VERSION ""

NS_ :

BS_:

BU_: TBOX IPK PEPS BCM EPS ABS AVAS ACU GW VCU PTC ACCM MMI Vector_XXX BMSH IPU OBC BMS
VAL_TABLE_ ACCM_ERROR 1 "Error" 0 "normal" ;
VAL_TABLE_ ACCM_CompressorPower 255 "低压高压都有,但是压缩机不工作" 254 "只有低压没有高压,压缩机不工作" ;
VAL_TABLE_ AVAS_AVASDisabledSts 1 "Disable" 0 "Enable" ;
VAL_TABLE_ VCU_ModeGearDisplaySts_BCM 4 "D" 3 "P" 2 "R" 1 "reserved" 0 "Display" ;
VAL_TABLE_ PTC_CoreOrIGBTOpenErr 1 "ture" 0 "false" ;
VAL_TABLE_ PTC_IGBTShrtErr 1 "ture" 0 "false" ;
VAL_TABLE_ PTC_CoreShrtErr 1 "ture" 0 "false" ;
VAL_TABLE_ PTC_HVOverCrntProtn 1 "ture" 0 "false" ;
VAL_TABLE_ PTC_VbatVtgProtn 1 "ture" 0 "false" ;
VAL_TABLE_ PTC_HVDisconnectProtn 1 "ture" 0 "false" ;
VAL_TABLE_ PTC_IGBTOverTemProtn 1 "ture" 0 "false" ;
VAL_TABLE_ PTC_ClntInltOverTemProtn 1 "ture" 0 "false" ;
VAL_TABLE_ PTC_ClntOtltOverTemProtn 1 "Ture" 0 "False" ;
VAL_TABLE_ PTC_VbatVtgUnstable 1 "Ture" 0 "False" ;
VAL_TABLE_ PTC_VbatVtgSnsrFlt 1 "Ture" 0 "False" ;
VAL_TABLE_ PTC_PCBTempSnsrFlt 1 "Ture" 0 "False" ;
VAL_TABLE_ PTC_HVCrntSnsrFlt 1 "Ture" 0 "False" ;
VAL_TABLE_ PTC_PCBOverTempProtn 1 "Ture" 0 "False" ;
VAL_TABLE_ VCU_IPK_MotFault 1 "Fault(故障)" 0 "Default(默认值)" ;
VAL_TABLE_ MMI_AntiPinchWarnSet 3 "Reserved" 2 "Enable Request" 1 "Disable Request" 0 "No Request" ;
VAL_TABLE_ MMI_AutoCloseWindowSet 3 "Reserved" 2 "Enable Request" 1 "Disable Request" 0 "No Request" ;
VAL_TABLE_ MMI_K15Off_AutounlockSet 3 "Reserved" 2 "Enable Request" 1 "Disable Request" 0 "No Request" ;
VAL_TABLE_ MMI_RKELockFeedbackSet 3 "Reserved" 2 "Enable Request

" 1 "Disable Request" 0 "No Request" ;

BO_ 3221225472 VECTOR__INDEPENDENT_SIG_MSG: 0 Vector__XXX
 SG_ ACU_PassengerAirbagStatus : 0|1@0+ (1,0) [0|1] "bit" Vector__XXX
 SG_ ACCM_ACCMError : 0|16@0+ (1,0) [0|8192] "bit" Vector__XXX

BO_ 555 PTC_Fault: 8 Vector__XXX
 SG_ PTC_IGBTTemp : 63|8@0+ (1,-40) [0|0] "℃" Vector__XXX
 SG_ PTC_CIntTempInlet : 47|8@0+ (1,-40) [0|0] "℃" Vector__XXX
 SG_ PTC_ActualCurrent : 39|8@0+ (0.25,0) [0|0] "A" Vector__XXX
 SG_ PTC_MmryFlt : 19|1@0+ (1,0) [0|1] "" Vector__XXX
 SG_ PTC_IGBTTemSnsrFlt : 20|1@0+ (1,0) [0|1] "" Vector__XXX
 SG_ PTC_ClntInltTemSnsrFlt : 21|1@0+ (1,0) [0|1] "" Vector__XXX
 SG_ PTC_ClntOtltTemSnsrFlt : 22|1@0+ (1,0) [0|1] "" Vector__XXX
 SG_ PTC_CommError : 23|1@0+ (1,0) [0|1] "" Vector__XXX
 SG_ PTC_CoreOrIGBTOpenErr : 8|1@0+ (1,0) [0|1] "" Vector__XXX
 SG_ PTC_IGBTShrtErr : 9|1@0+ (1,0) [0|1] "" Vector__XXX
 SG_ PTC_CoreShrtErr : 10|1@0+ (1,0) [0|1] "" Vector__XXX
 SG_ PTC_HVOverCrntProtn : 11|1@0+ (1,0) [0|1] "" Vector__XXX
 SG_ PTC_VbatVtgProtn : 12|1@0+ (1,0) [0|1] "" Vector__XXX
 SG_ PTC_HVDisconnectProtn : 13|1@0+ (1,0) [0|1] "" Vector__XXX
 SG_ PTC_IGBTOverTemProtn : 14|1@0+ (1,0) [0|1] "" Vector__XXX
 SG_ PTC_ClntInltOverTemProtn : 15|1@0+ (1,0) [0|1] "" Vector__XXX
 SG_ PTC_ClntOtltOverTemProtn : 0|1@0+ (1,0) [0|1] "" Vector__XXX
 SG_ PTC_VbatVtgUnstable : 1|1@0+ (1,0) [0|1] "" Vector__XXX
 SG_ PTC_VbatVtgSnsrFlt : 2|1@0+ (1,0) [0|1] "" Vector__XXX
 SG_ PTC_PCBTempSnsrFlt : 3|1@0+ (1,0) [0|1] "" Vector__XXX
 SG_ PTC_HVCrntSnsrFlt : 4|1@0+ (1,0) [0|1] "" Vector__XXX
 SG_ PTC_PCBOverTempProtn : 5|1@0+ (1,0) [0|1] "" Vector__XXX

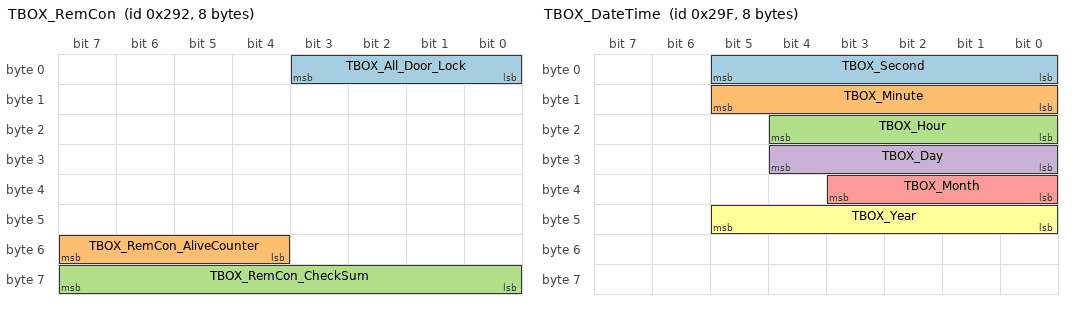
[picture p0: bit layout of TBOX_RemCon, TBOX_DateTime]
BO_ 658 TBOX_RemCon: 8 TBOX
 SG_ TBOX_All_Door_Lock : 3|4@0+ (1,0) [0|15] "bit"  BCM
 SG_ TBOX_RemCon_AliveCounter : 55|4@0+ (1,0) [0|15] "bit"  Vector_XXX
 SG_ TBOX_RemCon_CheckSum : 63|8@0+ (1,0) [0|255] "bit"  Vector_XXX

BO_ 259 TBOX_ResponseCode: 8 TBOX
 SG_ TBOX_ResponseCode : 7|64@0+ (1,0) [0|65535] "bit"  BCM

BO_ 671 TBOX_DateTime: 8 TBOX
 SG_ TBOX_Second : 5|6@0+ (1,0) [0|59] "s"  IPK,MMI
 SG_ TBOX_Minute : 13|6@0+ (1,0) [0|59] "m"  IPK,MMI
 SG_ TBOX_Hour : 20|5@0+ (1,0) [0|23] "h"  IPK,MMI
 SG_ TBOX_Day : 28|5@0+ (1,0) [1|31] "d"  IPK,MMI
 SG_ TBOX_Month : 35|4@0+ (1,0) [1|12] "m"  IPK,MMI
 SG_ TBOX_Year : 45|6@0+ (1,0) [0|63] "y"  IPK,MMI

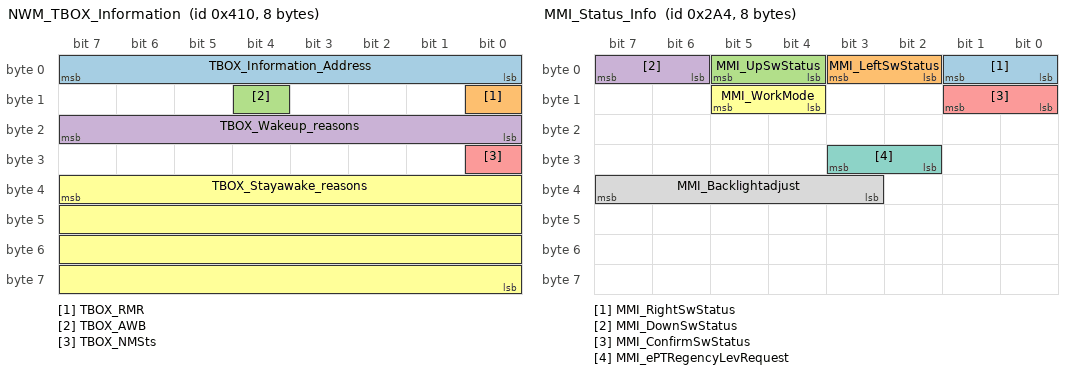
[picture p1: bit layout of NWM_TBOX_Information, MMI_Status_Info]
BO_ 1040 NWM_TBOX_Information: 8 TBOX
 SG_ TBOX_Information_Address : 7|8@0+ (1,0) [0|127] "bit"  Vector_XXX
 SG_ TBOX_RMR : 8|1@0+ (1,0) [0|1] "bit"  Vector_XXX
 SG_ TBOX_AWB : 12|1@0+ (1,0) [0|1] "bit"  Vector_XXX
 SG_ TBOX_Wakeup_reasons : 23|8@0+ (1,0) [0|255] "bit"  Vector_XXX
 SG_ TBOX_NMSts : 24|1@0+ (1,0) [0|1] "bit"  Vector_XXX
 SG_ TBOX_Stayawake_reasons : 39|32@0+ (1,0) [0|65535] "bit"  Vector_XXX

BO_ 676 MMI_Status_Info: 8 MMI
 SG_ MMI_RightSwStatus : 1|2@0+ (1,0) [0|3] "bit"  IPK
 SG_ MMI_LeftSwStatus : 3|2@0+ (1,0) [0|3] "bit"  IPK
 SG_ MMI_UpSwStatus : 5|2@0+ (1,0) [0|3] "bit"  IPK
 SG_ MMI_DownSwStatus : 7|2@0+ (1,0) [0|3] "bit"  IPK
 SG_ MMI_ConfirmSwStatus : 9|2@0+ (1,0) [0|3] "bit"  IPK
 SG_ MMI_WorkMode : 13|2@0+ (1,0) [0|1] "bit"  IPK
 SG_ MMI_ePTRegencyLevRequest : 27|2@0+ (1,0) [0|3] "bit"  VCU
 SG_ MMI_Backlightadjust : 39|5@0+ (1,0) [0|31] "bit"  IPK

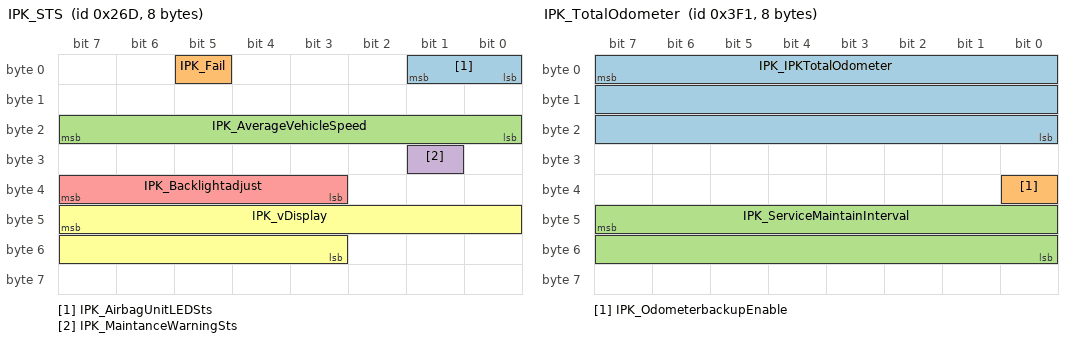
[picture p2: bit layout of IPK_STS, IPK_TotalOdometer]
BO_ 621 IPK_STS: 8 IPK
 SG_ IPK_AirbagUnitLEDSts : 1|2@0+ (1,0) [0|3] "bit"  Vector_XXX
 SG_ IPK_Fail : 5|1@0+ (1,0) [0|1] "bit"  Vector_XXX
 SG_ IPK_AverageVehicleSpeed : 23|8@0+ (1,0) [0|254] "KPH"  Vector_XXX
 SG_ IPK_MaintanceWarningSts : 25|1@0+ (1,0) [0|1] "bit"  MMI
 SG_ IPK_Backlightadjust : 39|5@0+ (1,0) [0|31] "bit"  MMI
 SG_ IPK_vDisplay : 47|13@0+ (0.05625,0) [0|460.688] "KPH"  Vector_XXX

BO_ 1009 IPK_TotalOdometer: 8 IPK
 SG_ IPK_IPKTotalOdometer : 7|24@0+ (0.1,0) [0|999999] "KM"  BCM,MMI,TBOX,AVAS,VCU,ACU,BMSH
 SG_ IPK_OdometerbackupEnable : 32|1@0+ (1,0) [0|1] "bit"  BCM,VCU,TBOX,MMI
 SG_ IPK_ServiceMaintainInterval : 47|16@0+ (1,0) [0|10000] "km"  MMI,TBOX

BO_ 1015 IPK_ODO_Consump: 8 IPK
 SG_ IPK_AveragePowerConsumption : 23|13@0+ (0.1,-99.9) [-99.9|99.9] "Kwh/100km"  TBOX
 SG_ IPK_InstantPowerConsumption : 39|13@0+ (0.1,-99.9) [-99.9|99.9] "Kwh/h"  TBOX

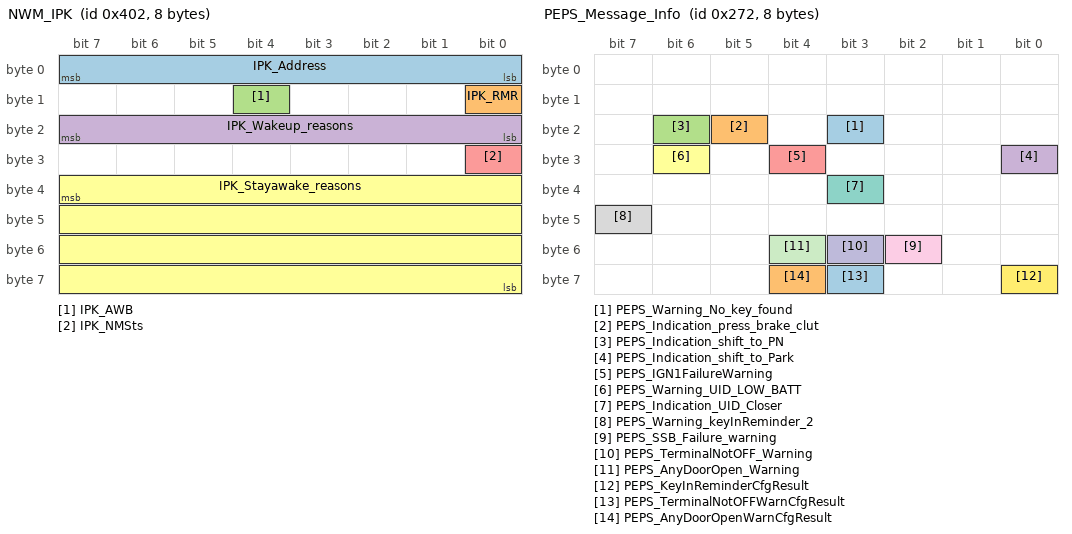
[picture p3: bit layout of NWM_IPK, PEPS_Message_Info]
BO_ 1026 NWM_IPK: 8 IPK
 SG_ IPK_Address : 7|8@0+ (1,0) [0|127] "bit"  Vector_XXX
 SG_ IPK_RMR : 8|1@0+ (1,0) [0|1] "bit"  Vector_XXX
 SG_ IPK_AWB : 12|1@0+ (1,0) [0|1] "bit"  Vector_XXX
 SG_ IPK_Wakeup_reasons : 23|8@0+ (1,0) [0|255] "bit"  Vector_XXX
 SG_ IPK_NMSts : 24|1@0+ (1,0) [0|1] "bit"  Vector_XXX
 SG_ IPK_Stayawake_reasons : 39|32@0+ (1,0) [0|65535] "bit"  Vector_XXX

BO_ 626 PEPS_Message_Info: 8 PEPS
 SG_ PEPS_Warning_No_key_found : 19|1@0+ (1,0) [0|1] "bit"  IPK
 SG_ PEPS_Indication_press_brake_clut : 21|1@0+ (1,0) [0|1] "bit"  IPK
 SG_ PEPS_Indication_shift_to_PN : 22|1@0+ (1,0) [0|1] "bit"  IPK
 SG_ PEPS_Indication_shift_to_Park : 24|1@0+ (1,0) [0|1] "bit"  IPK
 SG_ PEPS_IGN1FailureWarning : 28|1@0+ (1,0) [0|1] "bit"  IPK
 SG_ PEPS_Warning_UID_LOW_BATT : 30|1@0+ (1,0) [0|1] "bit"  IPK
 SG_ PEPS_Indication_UID_Closer : 35|1@0+ (1,0) [0|1] "bit"  IPK
 SG_ PEPS_Warning_keyInReminder_2 : 47|1@0+ (1,0) [0|1] "bit"  Vector_XXX
 SG_ PEPS_SSB_Failure_warning : 50|1@0+ (1,0) [0|1] "bit"  IPK
 SG_ PEPS_TerminalNotOFF_Warning : 51|1@0+ (1,0) [0|1] "bit"  Vector_XXX
 SG_ PEPS_AnyDoorOpen_Warning : 52|1@0+ (1,0) [0|1] "bit"  Vector_XXX
 SG_ PEPS_KeyInReminderCfgResult : 56|1@0+ (1,0) [0|1] "bit"  Vector_XXX
 SG_ PEPS_TerminalNotOFFWarnCfgResult : 59|1@0+ (1,0) [0|1] "bit"  Vector_XXX
 SG_ PEPS_AnyDoorOpenWarnCfgResult : 60|1@0+ (1,0) [0|1] "bit"  Vector_XXX

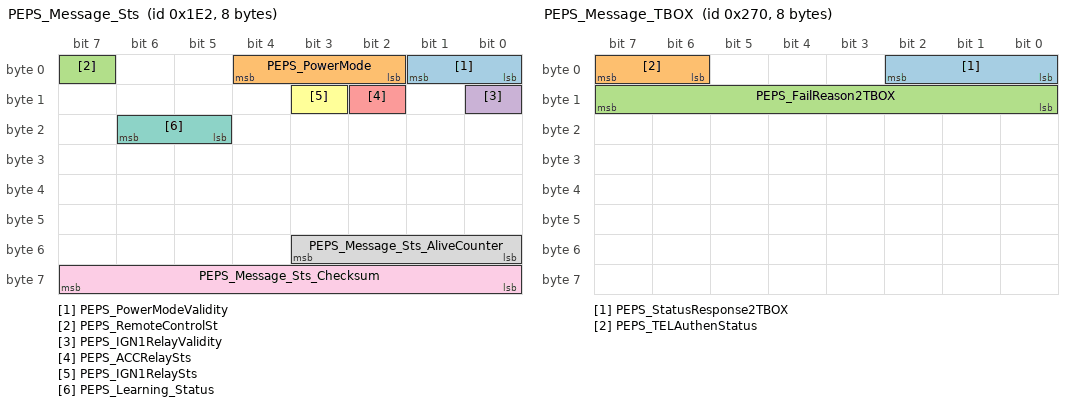
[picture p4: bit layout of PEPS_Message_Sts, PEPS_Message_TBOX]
BO_ 482 PEPS_Message_Sts: 8 PEPS
 SG_ PEPS_PowerModeValidity : 1|2@0+ (1,0) [0|3] "bit"  AVAS,VCU,MMI,TBOX,IPK,IPU,BMSH
 SG_ PEPS_PowerMode : 4|3@0+ (1,0) [0|7] "bit"  AVAS,VCU,MMI,TBOX,IPK,IPU,BMSH
 SG_ PEPS_RemoteControlSt : 7|1@0+ (1,0) [0|1] "bit"  TBOX
 SG_ PEPS_IGN1RelayValidity : 8|1@0+ (1,0) [0|1] "bit"  Vector_XXX
 SG_ PEPS_ACCRelaySts : 10|1@0+ (1,0) [0|1] "bit"  Vector_XXX
 SG_ PEPS_IGN1RelaySts : 11|1@0+ (1,0) [0|1] "bit"  Vector_XXX
 SG_ PEPS_Learning_Status : 22|2@0+ (1,0) [0|3] "bit"  Vector_XXX
 SG_ PEPS_Message_Sts_AliveCounter : 51|4@0+ (1,0) [0|15] "bit"  Vector_XXX
 SG_ PEPS_Message_Sts_Checksum : 63|8@0+ (1,0) [0|255] "bit"  Vector_XXX

BO_ 257 PEPS_IMMOCode: 8 PEPS
 SG_ PEPS_IMMOCode : 7|64@0+ (1,0) [0|65535] "bit"  IPU

BO_ 624 PEPS_Message_TBOX: 8 PEPS
 SG_ PEPS_StatusResponse2TBOX : 2|3@0+ (1,0) [0|7] "bit"  TBOX
 SG_ PEPS_TELAuthenStatus : 7|2@0+ (1,0) [0|3] "bit"  TBOX
 SG_ PEPS_FailReason2TBOX : 15|8@0+ (1,0) [0|255] "bit"  TBOX

BO_ 258 PEPS_TELChallengeCode: 8 PEPS
 SG_ PEPS_TELchallengeCode : 7|64@0+ (1,0) [0|65535] "bit"  TBOX

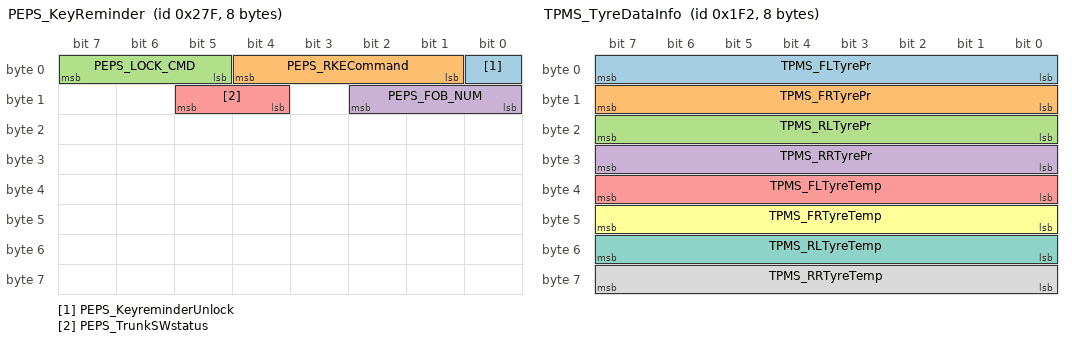
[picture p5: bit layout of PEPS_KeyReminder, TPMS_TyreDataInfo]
BO_ 639 PEPS_KeyReminder: 8 PEPS
 SG_ PEPS_KeyreminderUnlock : 0|1@0+ (1,0) [0|1] "bit"  Vector_XXX
 SG_ PEPS_RKECommand : 4|4@0+ (1,0) [0|15] "bit"  VCU
 SG_ PEPS_LOCK_CMD : 7|3@0+ (1,0) [0|7] "bit"  VCU
 SG_ PEPS_FOB_NUM : 10|3@0+ (1,0) [0|7] "bit"  Vector_XXX
 SG_ PEPS_TrunkSWstatus : 13|2@0+ (1,0) [0|3] "bit"  Vector_XXX

BO_ 497 TPMS_TyreWarn: 8 BCM
 SG_ TPMS_FLTyreWarn : 1|2@0+ (1,0) [0|3] "bit"  IPK
 SG_ TPMS_FLTyre_Temperature : 3|1@0+ (1,0) [0|1] "bit"  IPK
 SG_ TPMS_FLTyre_Fast_Leak : 4|1@0+ (1,0) [0|1] "bit"  IPK
 SG_ TPMS_FLTyre_Sensor_Failure : 5|1@0+ (1,0) [0|1] "bit"  IPK
 SG_ TPMS_FRTyreWarn : 9|2@0+ (1,0) [0|3] "bit"  IPK
 SG_ TPMS_FRTyre_Temperature : 11|1@0+ (1,0) [0|1] "bit"  IPK
 SG_ TPMS_FRTyre_Fast_Leak : 12|1@0+ (1,0) [0|1] "bit"  IPK
 SG_ TPMS_FRTyre_Sensor_Failure : 13|1@0+ (1,0) [0|1] "bit"  IPK
 SG_ TPMS_RLTyreWarn : 17|2@0+ (1,0) [0|3] "bit"  IPK
 SG_ TPMS_RLTyre_Temperature : 19|1@0+ (1,0) [0|1] "bit"  IPK
 SG_ TPMS_RLTyre_Fast_Leak : 20|1@0+ (1,0) [0|1] "bit"  IPK
 SG_ TPMS_RLTyre_Sensor_Failure : 21|1@0+ (1,0) [0|1] "bit"  IPK
 SG_ TPMS_RRTyreWarn : 25|2@0+ (1,0) [0|3] "bit"  IPK
 SG_ TPMS_RRTyre_Temperature : 27|1@0+ (1,0) [0|1] "bit"  IPK
 SG_ TPMS_RRTyre_Fast_Leak : 28|1@0+ (1,0) [0|1] "bit"  IPK
 SG_ TPMS_RRTyre_Sensor_Failure : 29|1@0+ (1,0) [0|1] "bit"  IPK
 SG_ TPMS_SystemSt : 33|2@0+ (1,0) [0|3] "bit"  IPK

BO_ 498 TPMS_TyreDataInfo: 8 BCM
 SG_ TPMS_FLTyrePr : 7|8@0+ (1.373,0) [0|348.742] "Kpa"  IPK
 SG_ TPMS_FRTyrePr : 15|8@0+ (1.373,0) [0|348.742] "Kpa"  IPK
 SG_ TPMS_RLTyrePr : 23|8@0+ (1.373,0) [0|348.742] "Kpa"  IPK
 SG_ TPMS_RRTyrePr : 31|8@0+ (1.373,0) [0|348.742] "Kpa"  IPK
 SG_ TPMS_FLTyreTemp : 39|8@0+ (1,-50) [-50|204] "°С"  IPK
 SG_ TPMS_FRTyreTemp : 47|8@0+ (1,-50) [-50|204] "°С"  IPK
 SG_ TPMS_RLTyreTemp : 55|8@0+ (1,-50) [-50|204] "°С"  IPK
 SG_ TPMS_RRTyreTemp : 63|8@0+ (1,-50) [-50|204] "°С"  IPK

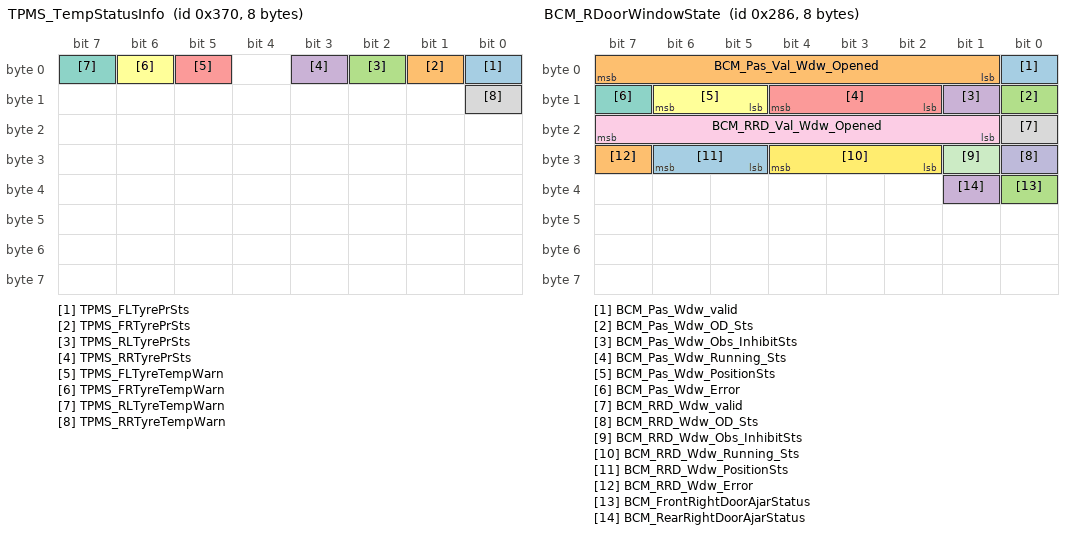
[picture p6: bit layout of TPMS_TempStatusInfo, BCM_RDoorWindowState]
BO_ 880 TPMS_TempStatusInfo: 8 BCM
 SG_ TPMS_FLTyrePrSts : 0|1@0+ (1,0) [0|1] "bit"  Vector_XXX
 SG_ TPMS_FRTyrePrSts : 1|1@0+ (1,0) [0|1] "bit"  Vector_XXX
 SG_ TPMS_RLTyrePrSts : 2|1@0+ (1,0) [0|1] "bit"  Vector_XXX
 SG_ TPMS_RRTyrePrSts : 3|1@0+ (1,0) [0|1] "bit"  Vector_XXX
 SG_ TPMS_FLTyreTempWarn : 5|1@0+ (1,0) [0|1] "bit"  Vector_XXX
 SG_ TPMS_FRTyreTempWarn : 6|1@0+ (1,0) [0|1] "bit"  Vector_XXX
 SG_ TPMS_RLTyreTempWarn : 7|1@0+ (1,0) [0|1] "bit"  Vector_XXX
 SG_ TPMS_RRTyreTempWarn : 8|1@0+ (1,0) [0|1] "bit"  Vector_XXX

BO_ 496 BCM_LightChimeReq: 8 BCM
 SG_ BCM_TurnIndicatorLeft : 0|1@0+ (1,0) [0|1] "bit"  TBOX,IPK
 SG_ BCM_TurnIndicatorRight : 3|1@0+ (1,0) [0|1] "bit"  TBOX,IPK
 SG_ BCM_TurnLeverSts : 5|2@0+ (1,0) [0|3] "bit"  Vector_XXX
 SG_ BCM_HighBeamLeverSts : 6|1@0+ (1,0) [0|1] "bit"  Vector_XXX
 SG_ BCM_HighBeamRelayFailSts : 7|1@0+ (1,0) [0|1] "bit"  Vector_XXX
 SG_ BCM_LowBeamSts : 8|1@0+ (1,0) [0|1] "bit"  IPK
 SG_ BCM_AutoLightSts : 9|1@0+ (1,0) [0|1] "bit"  Vector_XXX
 SG_ BCM_HighBeamSts : 10|1@0+ (1,0) [0|1] "bit"  IPK
 SG_ BCM_PositionLightSts : 11|1@0+ (1,0) [0|1] "bit"  IPK
 SG_ BCM_DayRunningLightSts : 12|1@0+ (1,0) [0|1] "bit"  IPK
 SG_ BCM_FollowMeHomACCMtive : 13|1@0+ (1,0) [0|1] "bit"  Vector_XXX
 SG_ BCM_FrontFogLightSts : 14|1@0+ (1,0) [0|1] "bit"  IPK
 SG_ BCM_RearFogLightSts : 15|1@0+ (1,0) [0|1] "bit"  IPK
 SG_ BCM_LightLeftOn : 16|1@0+ (1,0) [0|1] "bit"  IPK
 SG_ BCM_LightLeftwarning : 20|1@0+ (1,0) [0|1] "bit"  Vector_XXX
 SG_ BCM_HazardSts : 23|1@0+ (1,0) [0|1] "bit"  Vector_XXX
 SG_ BCM_LightChimeReq_AliveCounter : 51|4@0+ (1,0) [0|15] "bit"  Vector_XXX
 SG_ BCM_LightChimeReq_CheckSum : 63|8@0+ (1,0) [0|255] "bit"  Vector_XXX

BO_ 645 BCM_LDoorWindowState: 8 BCM
 SG_ BCM_Drv_Wdw_valid : 0|1@0+ (1,0) [0|1] "bit"  TBOX
 SG_ BCM_Drv_Val_Wdw_Opened : 7|7@0+ (1,0) [0|100] "%"  TBOX
 SG_ BCM_Drv_Wdw_OD_Sts : 8|1@0+ (1,0) [0|1] "bit"  TBOX
 SG_ BCM_Drv_Wdw_Obs_InhibitSts : 9|1@0+ (1,0) [0|1] "bit"  TBOX
 SG_ BCM_Drv_Wdw_Running_Sts : 12|3@0+ (1,0) [0|7] "bit"  TBOX
 SG_ BCM_Drv_Wdw_PositionSts : 14|2@0+ (1,0) [0|3] "bit"  TBOX
 SG_ BCM_Drv_Wdw_Error : 15|1@0+ (1,0) [0|1] "bit"  TBOX
 SG_ BCM_RLD_Wdw_valid : 16|1@0+ (1,0) [0|1] "bit"  TBOX
 SG_ BCM_RLD_Val_Wdw_Opened : 23|7@0+ (1,0) [0|100] "%"  TBOX
 SG_ BCM_RLD_Wdw_OD_Sts : 24|1@0+ (1,0) [0|1] "bit"  TBOX
 SG_ BCM_RLD_Wdw_Obs_InhibitSts : 25|1@0+ (1,0) [0|1] "bit"  TBOX
 SG_ BCM_RLD_Wdw_Running_Sts : 28|3@0+ (1,0) [0|7] "bit"  TBOX
 SG_ BCM_RLD_Wdw_PositionSts : 30|2@0+ (1,0) [0|3] "bit"  TBOX
 SG_ BCM_RLD_Wdw_Error : 31|1@0+ (1,0) [0|1] "bit"  TBOX
 SG_ BCM_FrontLeftDoorAjarStatus : 32|1@0+ (1,0) [0|1] "bit"  VCU,IPK,TBOX
 SG_ BCM_RearLeftDoorAjarStatus : 33|1@0+ (1,0) [0|1] "bit"  VCU,IPK,TBOX
 SG_ BCM_DoorLockStatusDrv : 37|2@0+ (1,0) [0|3] "bit"  VCU,OBC,TBOX
 SG_ BCM_RearMirrorFoldSetResp : 48|1@0+ (1,0) [0|1] "bit"  Vector_XXX
 SG_ BCM_AntiPinchWarnSetResp : 49|1@0+ (1,0) [0|1] "bit"  MMI

BO_ 646 BCM_RDoorWindowState: 8 BCM
 SG_ BCM_Pas_Wdw_valid : 0|1@0+ (1,0) [0|1] "bit"  TBOX
 SG_ BCM_Pas_Val_Wdw_Opened : 7|7@0+ (1,0) [0|100] "%"  TBOX
 SG_ BCM_Pas_Wdw_OD_Sts : 8|1@0+ (1,0) [0|1] "bit"  TBOX
 SG_ BCM_Pas_Wdw_Obs_InhibitSts : 9|1@0+ (1,0) [0|1] "bit"  TBOX
 SG_ BCM_Pas_Wdw_Running_Sts : 12|3@0+ (1,0) [0|7] "bit"  TBOX
 SG_ BCM_Pas_Wdw_PositionSts : 14|2@0+ (1,0) [0|3] "bit"  TBOX
 SG_ BCM_Pas_Wdw_Error : 15|1@0+ (1,0) [0|1] "bit"  TBOX
 SG_ BCM_RRD_Wdw_valid : 16|1@0+ (1,0) [0|1] "bit"  TBOX
 SG_ BCM_RRD_Val_Wdw_Opened : 23|7@0+ (1,0) [0|100] "%"  TBOX
 SG_ BCM_RRD_Wdw_OD_Sts : 24|1@0+ (1,0) [0|1] "bit"  TBOX
 SG_ BCM_RRD_Wdw_Obs_InhibitSts : 25|1@0+ (1,0) [0|1] "bit"  TBOX
 SG_ BCM_RRD_Wdw_Running_Sts : 28|3@0+ (1,0) [0|7] "bit"  TBOX
 SG_ BCM_RRD_Wdw_PositionSts : 30|2@0+ (1,0) [0|3] "bit"  TBOX
 SG_ BCM_RRD_Wdw_Error : 31|1@0+ (1,0) [0|1] "bit"  TBOX
 SG_ BCM_FrontRightDoorAjarStatus : 32|1@0+ (1,0) [0|1] "bit"  VCU,IPK,TBOX
 SG_ BCM_RearRightDoorAjarStatus : 33|1@0+ (1,0) [0|1] "bit"  VCU,IPK,TBOX

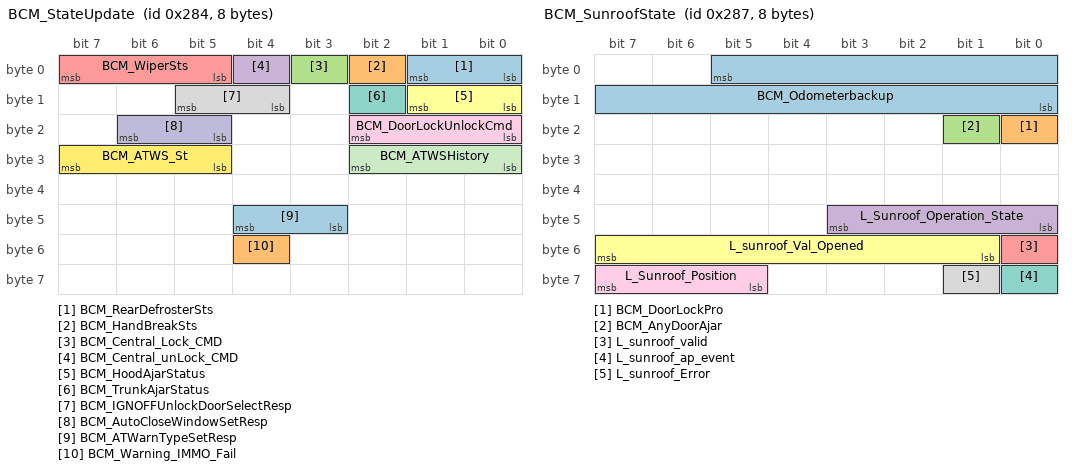
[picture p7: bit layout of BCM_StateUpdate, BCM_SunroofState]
BO_ 644 BCM_StateUpdate: 8 BCM
 SG_ BCM_RearDefrosterSts : 1|2@0+ (1,0) [0|3] "bit"  Vector_XXX
 SG_ BCM_HandBreakSts : 2|1@0+ (1,0) [0|1] "bit"  IPK,VCU
 SG_ BCM_Central_Lock_CMD : 3|1@0+ (1,0) [0|1] "bit"  Vector_XXX
 SG_ BCM_Central_unLock_CMD : 4|1@0+ (1,0) [0|1] "bit"  Vector_XXX
 SG_ BCM_WiperSts : 7|3@0+ (1,0) [0|7] "bit"  Vector_XXX
 SG_ BCM_HoodAjarStatus : 9|2@0+ (1,0) [0|3] "bit"  IPK,VCU
 SG_ BCM_TrunkAjarStatus : 10|1@0+ (1,0) [0|1] "bit"  IPK,VCU
 SG_ BCM_IGNOFFUnlockDoorSelectResp : 13|2@0+ (1,0) [0|3] "bit"  MMI
 SG_ BCM_DoorLockUnlockCmd : 18|3@0+ (1,0) [0|7] "bit"  Vector_XXX
 SG_ BCM_AutoCloseWindowSetResp : 22|2@0+ (1,0) [0|3] "bit"  MMI
 SG_ BCM_ATWSHistory : 26|3@0+ (1,0) [0|7] "bit"  Vector_XXX
 SG_ BCM_ATWS_St : 31|3@0+ (1,0) [0|7] "bit"  MMI,VCU
 SG_ BCM_ATWarnTypeSetResp : 44|2@0+ (1,0) [0|3] "bit"  MMI
 SG_ BCM_Warning_IMMO_Fail : 52|1@0+ (1,0) [0|1] "bit"  IPK

BO_ 647 BCM_SunroofState: 8 BCM
 SG_ BCM_Odometerbackup : 5|14@0+ (100,0) [0|1638200] "km"  IPK,VCU
 SG_ BCM_DoorLockPro : 16|1@0+ (1,0) [0|1] "bit"  Vector_XXX
 SG_ BCM_AnyDoorAjar : 17|1@0+ (1,0) [0|1] "bit"  Vector_XXX
 SG_ L_Sunroof_Operation_State : 43|4@0+ (1,0) [0|15] "bit"  Vector_XXX
 SG_ L_sunroof_valid : 48|1@0+ (1,0) [0|1] "bit"  Vector_XXX
 SG_ L_sunroof_Val_Opened : 55|7@0+ (1,0) [0|100] "%"  Vector_XXX
 SG_ L_sunroof_ap_event : 56|1@0+ (1,0) [0|1] "bit"  Vector_XXX
 SG_ L_sunroof_Error : 57|1@0+ (1,0) [0|1] "bit"  Vector_XXX
 SG_ L_Sunroof_Position : 63|3@0+ (1,0) [0|7] "bit"  Vector_XXX

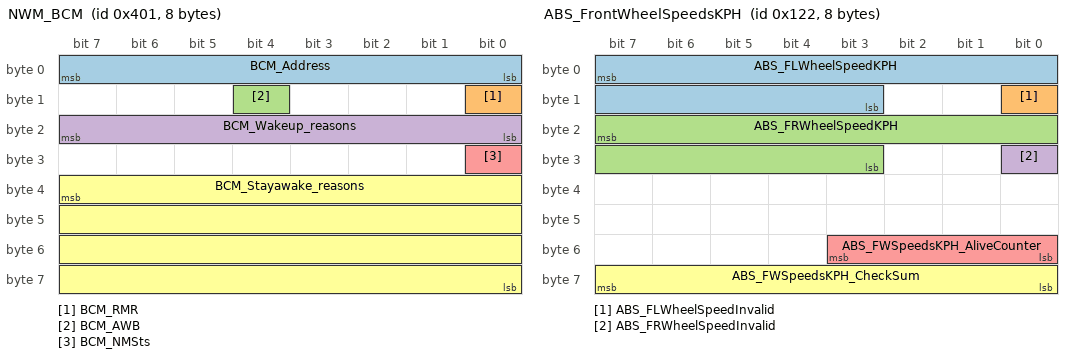
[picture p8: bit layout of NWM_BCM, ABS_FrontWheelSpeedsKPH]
BO_ 1025 NWM_BCM: 8 BCM
 SG_ BCM_Address : 7|8@0+ (1,0) [0|127] "bit"  Vector_XXX
 SG_ BCM_RMR : 8|1@0+ (1,0) [0|1] "bit"  Vector_XXX
 SG_ BCM_AWB : 12|1@0+ (1,0) [0|1] "bit"  Vector_XXX
 SG_ BCM_Wakeup_reasons : 23|8@0+ (1,0) [0|255] "bit"  Vector_XXX
 SG_ BCM_NMSts : 24|1@0+ (1,0) [0|1] "bit"  Vector_XXX
 SG_ BCM_Stayawake_reasons : 39|32@0+ (1,0) [0|65535] "bit"  Vector_XXX

BO_ 336 EPS_Sts: 8 EPS
 SG_ EPS_EpasFailed : 16|1@0+ (1,0) [0|1] "bit"  IPK

BO_ 704 EPS_Angel: 8 EPS
 SG_ EPS_StreeingWheelAngle : 7|16@0+ (1,-738) [-738|738] "deg"  MMI

BO_ 290 ABS_FrontWheelSpeedsKPH: 8 ABS
 SG_ ABS_FLWheelSpeedKPH : 7|13@0+ (0.05625,0) [0|460.688] "KPH"  BCM,VCU
 SG_ ABS_FLWheelSpeedInvalid : 8|1@0+ (1,0) [0|1] "bit"  BCM,VCU
 SG_ ABS_FRWheelSpeedKPH : 23|13@0+ (0.05625,0) [0|460.688] "KPH"  BCM,VCU
 SG_ ABS_FRWheelSpeedInvalid : 24|1@0+ (1,0) [0|1] "bit"  BCM,VCU
 SG_ ABS_FWSpeedsKPH_AliveCounter : 51|4@0+ (1,0) [0|15] "bit"  BCM,VCU
 SG_ ABS_FWSpeedsKPH_CheckSum : 63|8@0+ (1,0) [0|255] "bit"  BCM,VCU

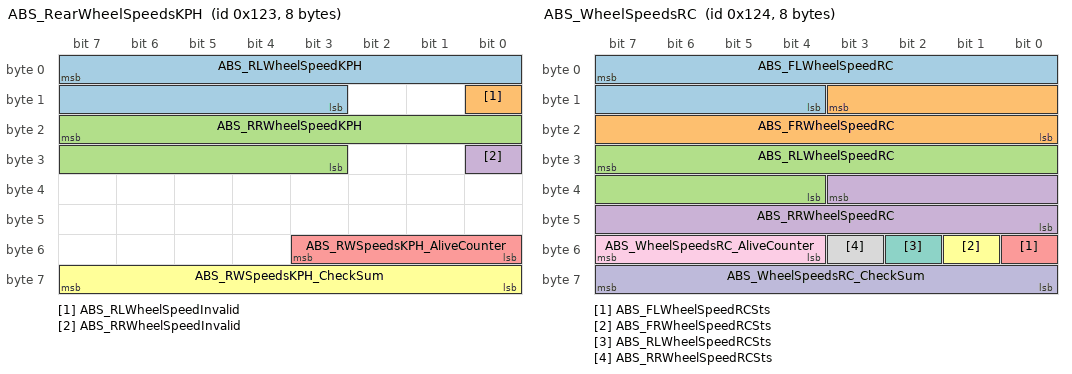
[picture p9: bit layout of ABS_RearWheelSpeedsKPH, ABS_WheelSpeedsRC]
BO_ 291 ABS_RearWheelSpeedsKPH: 8 ABS
 SG_ ABS_RLWheelSpeedKPH : 7|13@0+ (0.05625,0) [0|460.688] "KPH"  BCM,VCU
 SG_ ABS_RLWheelSpeedInvalid : 8|1@0+ (1,0) [0|1] "bit"  BCM,VCU
 SG_ ABS_RRWheelSpeedKPH : 23|13@0+ (0.05625,0) [0|460.688] "KPH"  BCM,VCU
 SG_ ABS_RRWheelSpeedInvalid : 24|1@0+ (1,0) [0|1] "bit"  BCM,VCU
 SG_ ABS_RWSpeedsKPH_AliveCounter : 51|4@0+ (1,0) [0|15] "bit"  BCM,VCU
 SG_ ABS_RWSpeedsKPH_CheckSum : 63|8@0+ (1,0) [0|255] "bit"  BCM,VCU

BO_ 292 ABS_WheelSpeedsRC: 8 ABS
 SG_ ABS_FLWheelSpeedRC : 7|12@0+ (1,0) [0|4095] "bit"  BCM
 SG_ ABS_FRWheelSpeedRC : 11|12@0+ (1,0) [0|4095] "bit"  BCM
 SG_ ABS_RLWheelSpeedRC : 31|12@0+ (1,0) [0|4095] "bit"  BCM
 SG_ ABS_RRWheelSpeedRC : 35|12@0+ (1,0) [0|4095] "bit"  BCM
 SG_ ABS_FLWheelSpeedRCSts : 48|1@0+ (1,0) [0|1] "bit"  BCM
 SG_ ABS_FRWheelSpeedRCSts : 49|1@0+ (1,0) [0|1] "bit"  BCM
 SG_ ABS_RLWheelSpeedRCSts : 50|1@0+ (1,0) [0|1] "bit"  BCM
 SG_ ABS_RRWheelSpeedRCSts : 51|1@0+ (1,0) [0|1] "bit"  BCM
 SG_ ABS_WheelSpeedsRC_AliveCounter : 55|4@0+ (1,0) [0|15] "bit"  BCM
 SG_ ABS_WheelSpeedsRC_CheckSum : 63|8@0+ (1,0) [0|255] "bit"  BCM

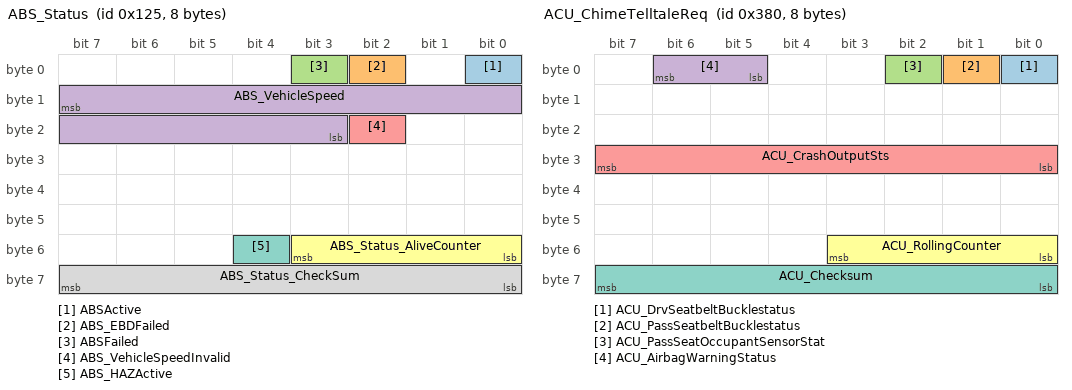
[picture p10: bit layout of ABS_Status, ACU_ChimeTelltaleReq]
BO_ 293 ABS_Status: 8 ABS
 SG_ ABSActive : 0|1@0+ (1,0) [0|1] "bit"  IPK,ACU,VCU
 SG_ ABS_EBDFailed : 2|1@0+ (1,0) [0|1] "bit"  IPK,ACU,TBOX
 SG_ ABSFailed : 3|1@0+ (1,0) [0|1] "bit"  TBOX,IPK,ACU
 SG_ ABS_VehicleSpeed : 15|13@0+ (0.05625,0) [0|460.63125] "KPH"  VCU,IPK,EPS,MMI,TBOX,BCM,AVAS,ACU
 SG_ ABS_VehicleSpeedInvalid : 18|1@0+ (1,0) [0|1] "bit"  VCU,IPK,EPS,MMI,TBOX,BCM,AVAS,ACU
 SG_ ABS_Status_AliveCounter : 51|4@0+ (1,0) [0|15] "bit"  VCU,IPK,TBOX,BCM,ACU
 SG_ ABS_HAZActive : 52|1@0+ (1,0) [0|1] "bit"  BCM
 SG_ ABS_Status_CheckSum : 63|8@0+ (1,0) [0|255] "bit"  VCU,IPK,TBOX,BCM,ACU

BO_ 690 AVAS_DisabledSts: 8 AVAS
 SG_ AVAS_AVASDisabledSts : 0|1@0+ (1,0) [0|1] "" Vector__XXX

BO_ 896 ACU_ChimeTelltaleReq: 8 ACU
 SG_ ACU_DrvSeatbeltBucklestatus : 0|1@0+ (1,0) [0|1] "bit"  IPK
 SG_ ACU_PassSeatbeltBucklestatus : 1|1@0+ (1,0) [0|1] "bit"  IPK
 SG_ ACU_PassSeatOccupantSensorStat : 2|1@0+ (1,0) [0|1] "bit"  IPK
 SG_ ACU_AirbagWarningStatus : 6|2@0+ (1,0) [0|3] "bit"  IPK
 SG_ ACU_CrashOutputSts : 31|8@0+ (1,0) [0|255] "bit"  VCU,BCM,BMS
 SG_ ACU_RollingCounter : 51|4@0+ (1,0) [0|15] "bit"  Vector_XXX
 SG_ ACU_Checksum : 63|8@0+ (1,0) [0|255] "bit"  Vector_XXX

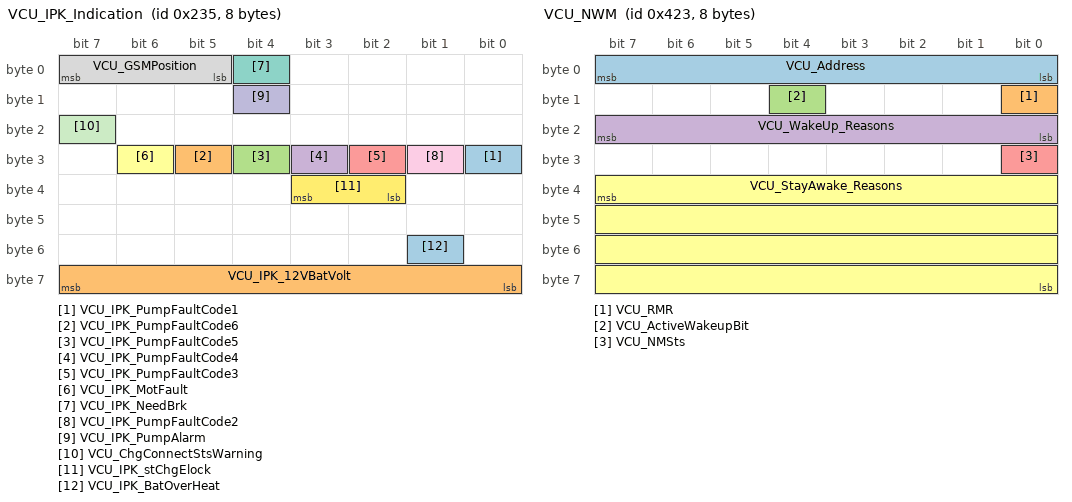
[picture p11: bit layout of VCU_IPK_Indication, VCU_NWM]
BO_ 565 VCU_IPK_Indication: 8 VCU
 SG_ VCU_IPK_PumpFaultCode1 : 24|1@0+ (1,0) [0|1] "" Vector__XXX
 SG_ VCU_IPK_PumpFaultCode6 : 29|1@0+ (1,0) [0|0] "" Vector__XXX
 SG_ VCU_IPK_PumpFaultCode5 : 28|1@0+ (1,0) [0|1] "" Vector__XXX
 SG_ VCU_IPK_PumpFaultCode4 : 27|1@0+ (1,0) [0|1] "" Vector__XXX
 SG_ VCU_IPK_PumpFaultCode3 : 26|1@0+ (1,0) [0|0] "" Vector__XXX
 SG_ VCU_IPK_MotFault : 30|1@1- (1,0) [0|1] "" Vector__XXX
 SG_ VCU_IPK_NeedBrk : 4|1@0+ (1,0) [0|1] "-"  IPK
 SG_ VCU_GSMPosition : 7|3@0+ (1,0) [0|7] "-"  IPK
 SG_ VCU_IPK_PumpFaultCode2 : 25|1@0+ (1,0) [0|1] "-"  Vector_XXX
 SG_ VCU_IPK_PumpAlarm : 12|1@0+ (1,0) [0|1] "-"  IPK
 SG_ VCU_ChgConnectStsWarning : 23|1@0+ (1,0) [0|1] "-"  IPK
 SG_ VCU_IPK_stChgElock : 35|2@0+ (1,0) [0|3] "-"  Vector_XXX
 SG_ VCU_IPK_BatOverHeat : 49|1@0+ (1,0) [0|1] "-"  IPK
 SG_ VCU_IPK_12VBatVolt : 63|8@0+ (0.0625,5) [0|20.875] "V"  IPK

BO_ 1059 VCU_NWM: 8 VCU
 SG_ VCU_Address : 7|8@0+ (1,0) [0|127] "bit"  Vector_XXX
 SG_ VCU_RMR : 8|1@0+ (1,0) [0|1] "bit"  Vector_XXX
 SG_ VCU_ActiveWakeupBit : 12|1@0+ (1,0) [0|1] "bit"  Vector_XXX
 SG_ VCU_WakeUp_Reasons : 23|8@0+ (1,0) [0|255] "bit"  Vector_XXX
 SG_ VCU_NMSts : 24|1@0+ (1,0) [0|1] "bit"  Vector_XXX
 SG_ VCU_StayAwake_Reasons : 39|32@0+ (1,0) [0|4294967295] "bit"  Vector_XXX

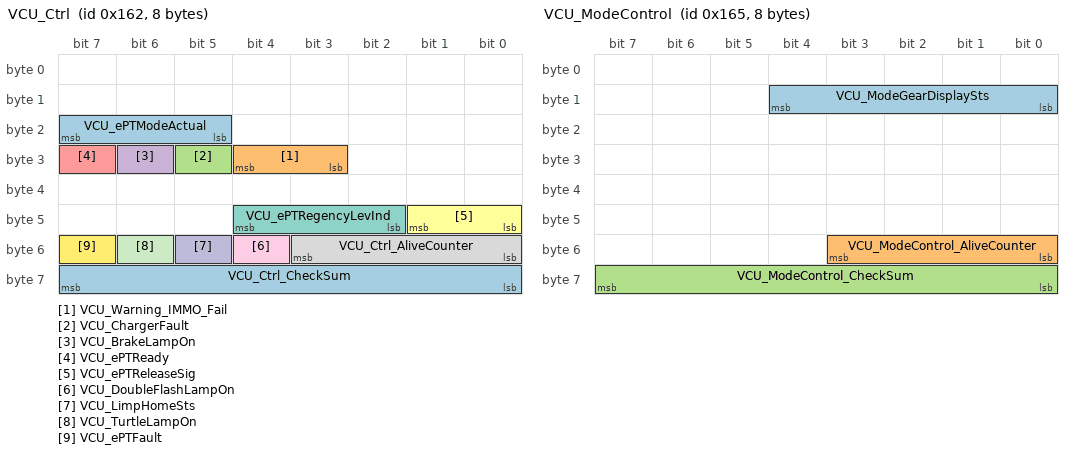
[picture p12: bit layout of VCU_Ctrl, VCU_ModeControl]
BO_ 354 VCU_Ctrl: 8 VCU
 SG_ VCU_ePTModeActual : 23|3@0+ (1,0) [0|7] "bit"  TBOX
 SG_ VCU_Warning_IMMO_Fail : 28|2@0+ (1,0) [0|3] "bit"  IPK
 SG_ VCU_ChargerFault : 29|1@0+ (1,0) [0|1] "bit"  IPK
 SG_ VCU_BrakeLampOn : 30|1@0+ (1,0) [0|1] "bit"  BCM
 SG_ VCU_ePTReady : 31|1@0+ (1,0) [0|1] "bit"  AVAS,MMI,IPK,EPS
 SG_ VCU_ePTReleaseSig : 41|2@0+ (1,0) [0|3] "bit"  BCM
 SG_ VCU_ePTRegencyLevInd : 44|3@0+ (1,0) [0|7] "bit"  IPK,MMI
 SG_ VCU_Ctrl_AliveCounter : 51|4@0+ (1,0) [0|15] "bit"  BCM
 SG_ VCU_DoubleFlashLampOn : 52|1@0+ (1,0) [0|1] "bit"  BCM
 SG_ VCU_LimpHomeSts : 53|1@0+ (1,0) [0|1] "bit"  IPK
 SG_ VCU_TurtleLampOn : 54|1@0+ (1,0) [0|1] "bit"  IPK
 SG_ VCU_ePTFault : 55|1@0+ (1,0) [0|1] "bit"  IPK
 SG_ VCU_Ctrl_CheckSum : 63|8@0+ (1,0) [0|255] "bit"  BCM

BO_ 357 VCU_ModeControl: 8 VCU
 SG_ VCU_ModeGearDisplaySts : 12|5@0+ (1,0) [0|31] "bit"  AVAS,IPK,MMI,EPS,TBOX
 SG_ VCU_ModeControl_AliveCounter : 51|4@0+ (1,0) [0|15] "bit"  Vector_XXX
 SG_ VCU_ModeControl_CheckSum : 63|8@0+ (1,0) [0|255] "bit"  Vector_XXX

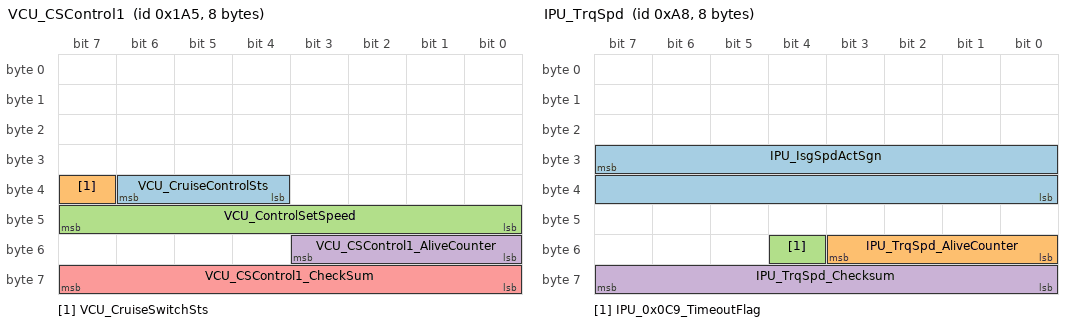
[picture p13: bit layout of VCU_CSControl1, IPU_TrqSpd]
BO_ 421 VCU_CSControl1: 8 VCU
 SG_ VCU_CruiseControlSts : 38|3@0+ (1,0) [0|7] "bit"  IPK
 SG_ VCU_CruiseSwitchSts : 39|1@0+ (1,0) [0|1] "bit"  IPK
 SG_ VCU_ControlSetSpeed : 47|8@0+ (1,0) [0|254] "kph"  IPK
 SG_ VCU_CSControl1_AliveCounter : 51|4@0+ (1,0) [0|15] "bit"  Vector_XXX
 SG_ VCU_CSControl1_CheckSum : 63|8@0+ (1,0) [0|255] "bit"  Vector_XXX

BO_ 1010 VCU_TotalOdometer: 8 VCU
 SG_ VCU_Odometerbackup : 7|14@0+ (100,0) [0|1638200] "km"  IPK

BO_ 544 OBC_Sts: 8 GW
 SG_ OBC_OnBdChrgrCCline : 47|2@0+ (1,0) [0|3] "bit"  IPK
 SG_ OBC_0x2B6_TimeoutFlag : 55|1@0+ (1,0) [0|1] "bit"  IPK

BO_ 168 IPU_TrqSpd: 8 GW
 SG_ IPU_IsgSpdActSgn : 31|16@0+ (1,-14000) [-14000|14000] "RPM"  IPK
 SG_ IPU_TrqSpd_AliveCounter : 51|4@0+ (1,0) [0|15] "bit"  Vector_XXX
 SG_ IPU_0x0C9_TimeoutFlag : 52|1@0+ (1,0) [0|1] "bit"  IPK
 SG_ IPU_TrqSpd_Checksum : 63|8@0+ (1,0) [0|255] "bit"  Vector_XXX

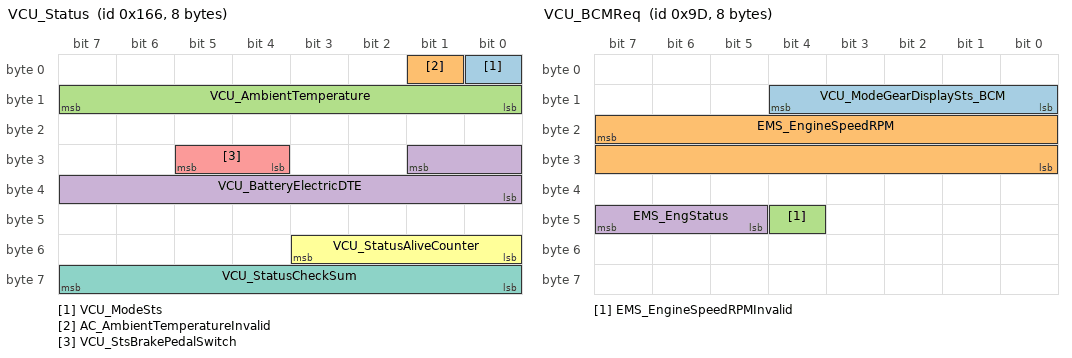
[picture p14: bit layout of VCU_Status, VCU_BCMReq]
BO_ 358 VCU_Status: 8 VCU
 SG_ VCU_ModeSts : 0|1@0+ (1,0) [0|1] "bit"  BCM,IPK
 SG_ AC_AmbientTemperatureInvalid : 1|1@0+ (1,0) [0|1] "bit"  IPK
 SG_ VCU_AmbientTemperature : 15|8@0+ (0.5,-40) [-40|60] "℃"  IPK
 SG_ VCU_BatteryElectricDTE : 25|10@0+ (1,0) [0|999] "km"  IPK
 SG_ VCU_StsBrakePedalSwitch : 29|2@0+ (1,0) [0|3] "-"  BCM,ABS,TBOX
 SG_ VCU_StatusAliveCounter : 51|4@0+ (1,0) [0|15] "bit"  ABS,BCM
 SG_ VCU_StatusCheckSum : 63|8@0+ (1,0) [0|255] "bit"  ABS,BCM

BO_ 157 VCU_BCMReq: 8 VCU
 SG_ VCU_ModeGearDisplaySts_BCM : 12|5@0+ (1,0) [0|0] "" Vector__XXX
 SG_ EMS_EngineSpeedRPM : 23|16@0+ (0.25,0) [0|16383.25] "RPM"  BCM
 SG_ EMS_EngineSpeedRPMInvalid : 44|1@0+ (1,0) [0|1] "bit"  BCM
 SG_ EMS_EngStatus : 47|3@0+ (1,0) [0|7] "bit"  BCM

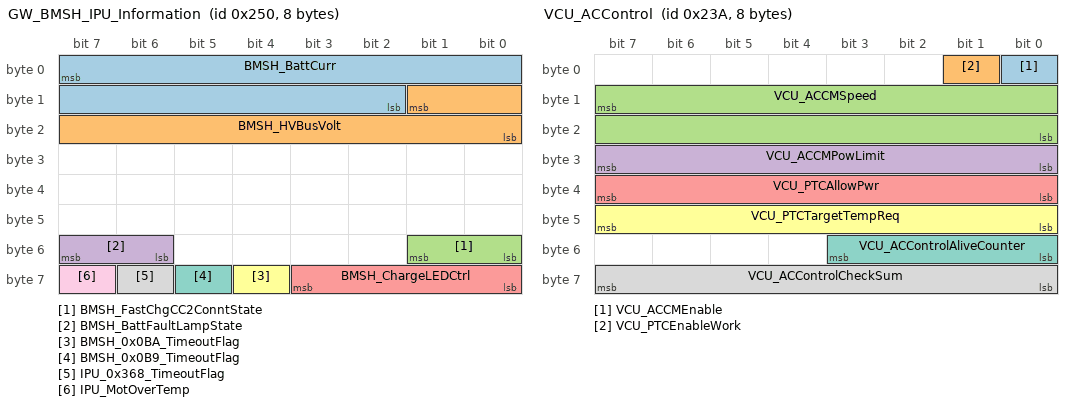
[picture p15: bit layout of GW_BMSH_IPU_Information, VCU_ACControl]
BO_ 592 GW_BMSH_IPU_Information: 8 GW
 SG_ BMSH_BattCurr : 7|14@0+ (0.1,-500) [-500|500] "A"  IPK
 SG_ BMSH_HVBusVolt : 9|10@0+ (1,0) [0|600] "V"  IPK
 SG_ BMSH_FastChgCC2ConntState : 49|2@0+ (1,0) [0|2] "bit"  IPK
 SG_ BMSH_BattFaultLampState : 55|2@0+ (1,0) [0|3] "bit"  IPK
 SG_ BMSH_ChargeLEDCtrl : 59|4@0+ (1,0) [0|7] "bit"  IPK,TBOX
 SG_ BMSH_0x0BA_TimeoutFlag : 60|1@0+ (1,0) [0|1] "bit"  IPK
 SG_ BMSH_0x0B9_TimeoutFlag : 61|1@0+ (1,0) [0|1] "bit"  IPK,TBOX
 SG_ IPU_0x368_TimeoutFlag : 62|1@0+ (1,0) [0|1] "bit"  IPK
 SG_ IPU_MotOverTemp : 63|1@0+ (1,0) [0|1] "bit"  IPK

BO_ 256 IPU_PEPSAuth: 8 GW
 SG_ IPU_PEPSAuth : 7|64@0+ (1,0) [0|65535] "bit"  BCM

BO_ 756 BMSH_Info: 8 GW
 SG_ BMSH_BattSOCDisp : 15|10@0+ (0.1,0) [0|100] "%"  IPK

BO_ 379 BMSH_Battery_chgstate: 8 GW
 SG_ BMSH_ACChgTimeRemain : 35|11@0+ (1,0) [0|1800] "min"  IPK

BO_ 570 VCU_ACControl: 8 VCU
 SG_ VCU_ACCMEnable : 0|1@0+ (1,0) [0|1] "bit"  ACCM
 SG_ VCU_PTCEnableWork : 1|1@0+ (1,0) [0|1] "bit"  PTC
 SG_ VCU_ACCMSpeed : 15|16@0+ (1,0) [0|6500] "rpm"  ACCM
 SG_ VCU_ACCMPowLimit : 31|8@0+ (100,0) [0|8000] "W"  ACCM
 SG_ VCU_PTCAllowPwr : 39|8@0+ (100,0) [0|8000] "W"  PTC
 SG_ VCU_PTCTargetTempReq : 47|8@0+ (1,-40) [-40|210] "℃"  PTC
 SG_ VCU_ACControlAliveCounter : 51|4@0+ (1,0) [0|15] "bit"  PTC,ACCM
 SG_ VCU_ACControlCheckSum : 63|8@0+ (1,0) [0|255] "bit"  PTC,ACCM

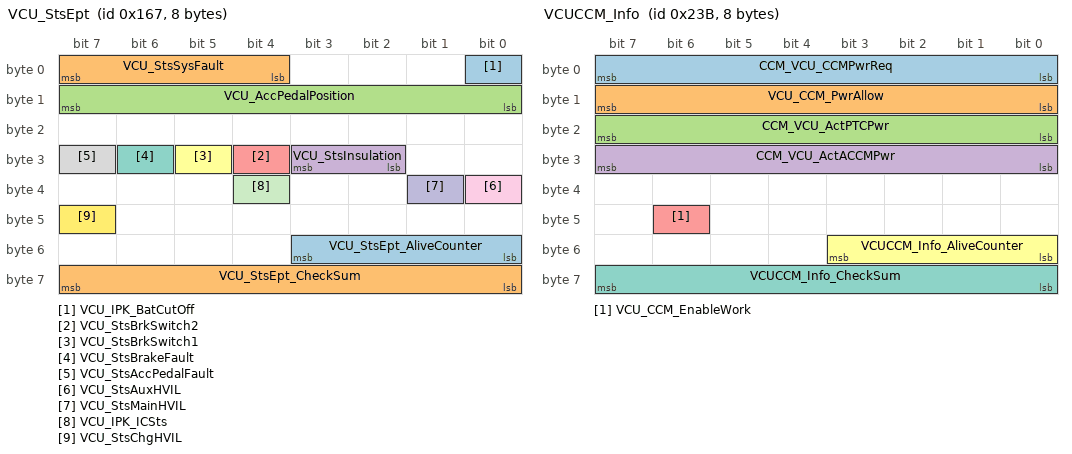
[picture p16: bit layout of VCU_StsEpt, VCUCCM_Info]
BO_ 359 VCU_StsEpt: 8 VCU
 SG_ VCU_IPK_BatCutOff : 0|1@0+ (1,0) [0|1] "-"  IPK
 SG_ VCU_StsSysFault : 7|4@0+ (1,0) [0|15] "-"  Vector_XXX
 SG_ VCU_AccPedalPosition : 15|8@0+ (0.4,0) [0|100] "%"  TBOX
 SG_ VCU_StsInsulation : 27|2@0+ (1,0) [0|3] "-"  Vector_XXX
 SG_ VCU_StsBrkSwitch2 : 28|1@0+ (1,0) [0|1] "-"  Vector_XXX
 SG_ VCU_StsBrkSwitch1 : 29|1@0+ (1,0) [0|1] "-"  Vector_XXX
 SG_ VCU_StsBrakeFault : 30|1@0+ (1,0) [0|1] "-"  TBOX
 SG_ VCU_StsAccPedalFault : 31|1@0+ (1,0) [0|1] "-"  TBOX
 SG_ VCU_StsAuxHVIL : 32|1@0+ (1,0) [0|1] "-"  Vector_XXX
 SG_ VCU_StsMainHVIL : 33|1@0+ (1,0) [0|1] "-"  Vector_XXX
 SG_ VCU_IPK_ICSts : 36|1@0+ (1,0) [0|1] "-"  IPK
 SG_ VCU_StsChgHVIL : 47|1@0+ (1,0) [0|1] "-"  Vector_XXX
 SG_ VCU_StsEpt_AliveCounter : 51|4@0+ (1,0) [0|15] "-"  Vector_XXX
 SG_ VCU_StsEpt_CheckSum : 63|8@0+ (1,0) [0|255] "-"  Vector_XXX

BO_ 571 VCUCCM_Info: 8 VCU
 SG_ CCM_VCU_CCMPwrReq : 7|8@0+ (0.1,0) [0|25.4] "KW"  Vector_XXX
 SG_ VCU_CCM_PwrAllow : 15|8@0+ (0.1,0) [0|25.4] "KW"  Vector_XXX
 SG_ CCM_VCU_ActPTCPwr : 23|8@0+ (0.1,0) [0|25.4] "KW"  Vector_XXX
 SG_ CCM_VCU_ActACCMPwr : 31|8@0+ (0.1,0) [0|25.4] "KW"  Vector_XXX
 SG_ VCU_CCM_EnableWork : 46|1@0+ (1,0) [0|1] "-"  Vector_XXX
 SG_ VCUCCM_Info_AliveCounter : 51|4@0+ (1,0) [0|15] "-"  Vector_XXX
 SG_ VCUCCM_Info_CheckSum : 63|8@0+ (1,0) [0|255] "-"  Vector_XXX

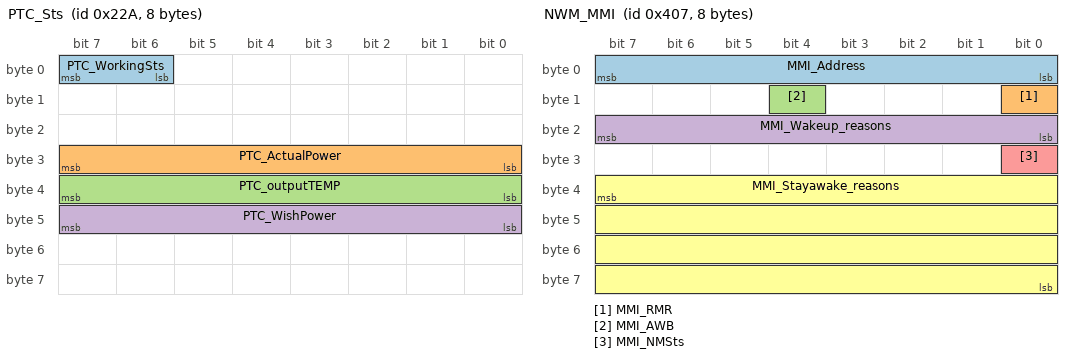
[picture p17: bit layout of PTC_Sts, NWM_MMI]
BO_ 554 PTC_Sts: 8 PTC
 SG_ PTC_WorkingSts : 7|2@0+ (1,0) [0|3] "bit"  VCU
 SG_ PTC_ActualPower : 31|8@0+ (0.1,0) [0|25.3] "KW"  VCU
 SG_ PTC_outputTEMP : 39|8@0+ (1,-40) [-40|100] "℃"  VCU
 SG_ PTC_WishPower : 47|8@0+ (0.1,0) [0|25.3] "KW"  VCU

BO_ 550 ACCM_Sts: 8 ACCM
 SG_ ACCM_InnerCommunError : 46|1@0+ (1,0) [0|0] "" Vector__XXX
 SG_ ACCM_SelfTestFail : 45|1@0+ (1,0) [0|0] "" Vector__XXX
 SG_ ACCM_CommunFail : 44|1@0+ (1,0) [0|0] "" Vector__XXX
 SG_ ACCM_StartFail : 43|1@0+ (1,0) [0|0] "" Vector__XXX
 SG_ ACCM_Stepout : 42|1@0+ (1,0) [0|0] "" Vector__XXX
 SG_ ACCM_CurProt : 41|1@0+ (1,0) [0|0] "" Vector__XXX
 SG_ ACCM_OverTemp : 40|1@0+ (1,0) [0|0] "" Vector__XXX
 SG_ ACCM_PowerLimit : 39|1@0+ (1,0) [0|0] "" Vector__XXX
 SG_ ACCM_CurLimit : 38|1@0+ (1,0) [0|0] "" Vector__XXX
 SG_ ACCM_DataProError : 37|1@0+ (1,0) [0|0] "" Vector__XXX
 SG_ ACCM_StandbyLowVolt : 36|1@0+ (1,0) [0|0] "" Vector__XXX
 SG_ ACCM_StandbyOverVolt : 35|1@0+ (1,0) [0|0] "" Vector__XXX
 SG_ ACCM_WokLowVolt : 34|1@0+ (1,0) [0|0] "" Vector__XXX
 SG_ ACCM_OverVolt : 33|1@0+ (1,0) [0|0] "" Vector__XXX
 SG_ ACCM_OverCur : 32|1@0+ (1,0) [0|0] "" Vector__XXX
 SG_ ACCM_CompressorPower : 7|8@0+ (0.1,0) [0|25.3] "KW"  VCU
 SG_ ACCM_CompressorSpeed : 15|8@0+ (50,0) [0|6500] "rpm"  VCU
 SG_ ACCM_CompressorVolt : 31|8@0+ (2,0) [0|510] "V"  Vector_XXX
 SG_ ACCM_RollingCounter : 51|4@0+ (1,0) [0|15] "bit"  Vector_XXX
 SG_ ACCM_ACCMSts : 55|4@0+ (1,0) [0|3] "bit"  VCU
 SG_ ACCM_Checksum : 63|8@0+ (1,0) [0|255] "bit"  Vector_XXX

BO_ 1031 NWM_MMI: 8 MMI
 SG_ MMI_Address : 7|8@0+ (1,0) [0|127] "bit"  Vector_XXX
 SG_ MMI_RMR : 8|1@0+ (1,0) [0|1] "bit"  Vector_XXX
 SG_ MMI_AWB : 12|1@0+ (1,0) [0|1] "bit"  Vector_XXX
 SG_ MMI_Wakeup_reasons : 23|8@0+ (1,0) [0|255] "bit"  Vector_XXX
 SG_ MMI_NMSts : 24|1@0+ (1,0) [0|1] "bit"  Vector_XXX
 SG_ MMI_Stayawake_reasons : 39|32@0+ (1,0) [0|65535] "bit"  Vector_XXX

BO_ 679 MMI_Configuration_Info: 8 MMI
 SG_ MMI_Maintanceclear_inform : 8|1@0+ (1,0) [0|1] "bit"  IPK
 SG_ MMI_AVASDisabledSet : 23|2@0+ (1,0) [0|3] "bit"  AVAS

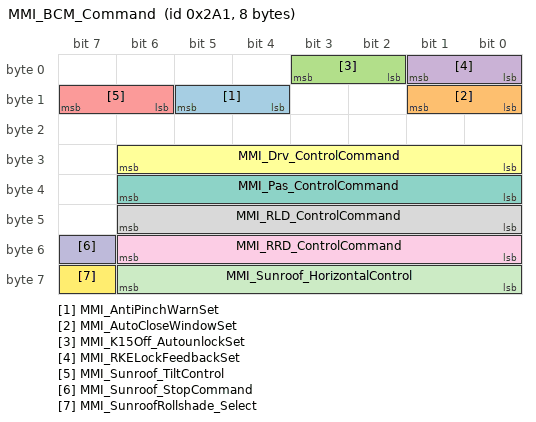
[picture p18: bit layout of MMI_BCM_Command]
BO_ 673 MMI_BCM_Command: 8 MMI
 SG_ MMI_AntiPinchWarnSet : 13|2@0- (1,0) [0|3] "" Vector__XXX
 SG_ MMI_AutoCloseWindowSet : 9|2@0- (1,0) [0|3] "" Vector__XXX
 SG_ MMI_K15Off_AutounlockSet : 3|2@0+ (1,0) [0|3] "" Vector__XXX
 SG_ MMI_RKELockFeedbackSet : 1|2@0+ (1,0) [0|3] "" Vector__XXX
 SG_ MMI_Sunroof_TiltControl : 15|2@0+ (1,0) [0|3] "bit"  BCM
 SG_ MMI_Drv_ControlCommand : 30|7@0+ (1,0) [0|100] "%"  BCM
 SG_ MMI_Pas_ControlCommand : 38|7@0+ (1,0) [0|100] "%"  BCM
 SG_ MMI_RLD_ControlCommand : 46|7@0+ (1,0) [0|100] "%"  BCM
 SG_ MMI_RRD_ControlCommand : 54|7@0+ (1,0) [0|100] "%"  BCM
 SG_ MMI_Sunroof_StopCommand : 55|1@0+ (1,0) [0|1] "bit"  BCM
 SG_ MMI_Sunroof_HorizontalControl : 62|7@0+ (1,0) [0|100] "%"  BCM
 SG_ MMI_SunroofRollshade_Select : 63|1@0+ (1,0) [0|1] "bit"  BCM

CM_ BO_ 3221225472 "This is a message for not used signals, created by Vector CANdb++ DBC OLE DB Provider.";
CM_ SG_ 3221225472 ACU_PassengerAirbagStatus "Signal from ACU for PAB on/off indicator display on IPK
ACU信号提示副驾驶座安全气囊状态";
CM_ SG_ 658 TBOX_All_Door_Lock "Signal from TBOX";
CM_ SG_ 658 TBOX_RemCon_AliveCounter "signal couting the times of this message";
CM_ SG_ 658 TBOX_RemCon_CheckSum "CRC code to check the data integrity";
CM_ BO_ 259 "远程启动需求";
CM_ SG_ 671 TBOX_Second "Second秒";
CM_ SG_ 671 TBOX_Minute "Minute分";
CM_ SG_ 671 TBOX_Hour "Hour小时";
CM_ SG_ 671 TBOX_Day "day天";
CM_ SG_ 671 TBOX_Month "Month月";
CM_ SG_ 671 TBOX_Year "Year年，基础年份为2000年";
CM_ BO_ 1040 "TBOX Network management Message";
CM_ SG_ 1040 TBOX_Information_Address "ECU Address";
CM_ SG_ 1040 TBOX_RMR "Repeat Message Request";
CM_ SG_ 1040 TBOX_AWB "Active Wakeup Bit";
CM_ SG_ 1040 TBOX_Wakeup_reasons "Clarify with supplier(LG,ZTE,FLC)";
CM_ SG_ 1040 TBOX_NMSts "The bit is used to indicate network management state. It's only used for test.";
CM_ SG_ 1040 TBOX_Stayawake_reasons "Clarify with supplier(LG,ZTE,FLC)";
CM_ BO_ 676 "Transmitted by MMI, including Switch status, Skin Mode signal";
CM_ SG_ 676 MMI_RightSwStatus "Indicate the Right Switch Action in the steering wheel";
CM_ SG_ 676 MMI_LeftSwStatus "Indicate the Left Switch Action in the steering wheel";
CM_ SG_ 676 MMI_UpSwStatus "Indicate the Up Switch Action in the steering wheel";
CM_ SG_ 676 MMI_DownSwStatus "Indicate the Down Switch Action in the steering wheel";
CM_ SG_ 676 MMI_ConfirmSwStatus "Indicate the Confirm Switch Action in the steering wheel";
CM_ SG_ 676 MMI_WorkMode "Indicate which ECU is controlled by the Button in the steering wheel ,MMI mode or IPK mode";
CM_ SG_ 676 MMI_ePTRegencyLevRequest "Switch of Ept Regency Level on MMI";
CM_ SG_ 676 MMI_Backlightadjust "Adjust the backlight";
CM_ BO_ 621 "Transmitted by IPK , including cluster status singals";
CM_ SG_ 621 IPK_AirbagUnitLEDSts "ACU Status check feedback";
CM_ SG_ 621 IPK_Fail "Error in the IPK control unit";
CM_ SG_ 621 IPK_AverageVehicleSpeed "Average Vehicle Speed";
CM_ SG_ 621 IPK_MaintanceWarningSts "IPK sends the maintance warning status";
CM_ SG_ 621 IPK_Backlightadjust "Adjust the backlight ";
CM_ SG_ 621 IPK_vDisplay "the vehicle speed displayed in IP";
CM_ BO_ 1009 "Transmitted by IPK , including Total Odometer";
CM_ SG_ 1009 IPK_IPKTotalOdometer "the total odometer displayed in IPK";
CM_ SG_ 1009 IPK_OdometerbackupEnable "Flag to enable other nodes to do odometer backup, IPK check its odometer when IGN ON, and set the flag if odometer is plausible, and clear the flag at IGN OFF";
CM_ SG_ 1009 IPK_ServiceMaintainInterval "Maintenance Interval";
CM_ BO_ 1015 "Transmitted by IPK, including";
CM_ SG_ 1015 IPK_AveragePowerConsumption "Indicate average power consumption";
CM_ SG_ 1015 IPK_InstantPowerConsumption "Indicate instant power consumption";
CM_ BO_ 1026 "IPK Network management Message";
CM_ SG_ 1026 IPK_Address "ECU Address";
CM_ SG_ 1026 IPK_RMR "Repeat Message Request";
CM_ SG_ 1026 IPK_AWB "Active Wakeup Bit";
CM_ SG_ 1026 IPK_NMSts "The bit is used to indicate network management state. It's only used for test.";
CM_ BO_ 626 "Transmitted by PEPS , including PEPS singals";
CM_ SG_ 626 PEPS_Warning_No_key_found "The driver shall be informed, if no key find when ACC/ON and any door is open or from open to close.";
CM_ SG_ 626 PEPS_Indication_press_brake_clut "The driver shall be informed, if he has to press brake (DCT/CVT)
The driver shall be informed, if he has to press Clutch (MT)";
CM_ SG_ 626 PEPS_Indication_shift_to_PN " The driver shall be informed, if he has to shift lever in P or N";
CM_ SG_ 626 PEPS_Indication_shift_to_Park "shift the lever in position P to stop";
CM_ SG_ 626 PEPS_IGN1FailureWarning "warning when IGN1 output or input has problem";
CM_ SG_ 626 PEPS_Warning_UID_LOW_BATT "Key Low Battery";
CM_ SG_ 626 PEPS_Indication_UID_Closer "get UID closer to start";
CM_ SG_ 626 PEPS_Warning_keyInReminder_2 "When the key is forgot in the Car and vehicle is locked, but one of door change from open to close within 500ms, system send out warning and inform BCM unlock the vehicle";
CM_ SG_ 626 PEPS_SSB_Failure_warning "SSB Failure warning";
CM_ SG_ 626 PEPS_TerminalNotOFF_Warning "warning when door lock but ignition is not off";
CM_ SG_ 626 PEPS_AnyDoorOpen_Warning "warning when door lock but any door is open";
CM_ SG_ 626 PEPS_KeyInReminderCfgResult "The key in reminder option result";
CM_ SG_ 626 PEPS_TerminalNotOFFWarnCfgResult "Lock warning when terminal state is not OFF result";
CM_ SG_ 626 PEPS_AnyDoorOpenWarnCfgResult "Lock warning when any door is open result";
CM_ BO_ 482 "Transmitted by PEPS , including PEPS singals";
CM_ SG_ 482 PEPS_PowerModeValidity "PEPS Power Distribution StatusValidity bit";
CM_ SG_ 482 PEPS_PowerMode "PEPS Power Distribution Status";
CM_ SG_ 482 PEPS_RemoteControlSt "PEPS remote control status";
CM_ SG_ 482 PEPS_IGN1RelayValidity "IGN1 output validity";
CM_ SG_ 482 PEPS_ACCRelaySts "ACC output status";
CM_ SG_ 482 PEPS_IGN1RelaySts "IGN1 output status";
CM_ SG_ 482 PEPS_Learning_Status "PEPS System learning status";
CM_ SG_ 482 PEPS_Message_Sts_AliveCounter "message alive counter";
CM_ SG_ 482 PEPS_Message_Sts_Checksum "message checksum";
CM_ BO_ 257 "Transmitted by PEPS";
CM_ BO_ 624 "Transmitted by PEPS";
CM_ SG_ 624 PEPS_StatusResponse2TBOX "PEPS send response to TBOX";
CM_ SG_ 624 PEPS_TELAuthenStatus "AuthenStatus";
CM_ SG_ 624 PEPS_FailReason2TBOX "PEPS send fail reason to TBOX";
CM_ BO_ 258 "Transmitted by PEPS";
CM_ SG_ 258 PEPS_TELchallengeCode "Challenge code";
CM_ BO_ 639 "Transmitted by PEPS";
CM_ SG_ 639 PEPS_KeyreminderUnlock "KeyreminderUnlock";
CM_ SG_ 639 PEPS_RKECommand "PEPS Remote Key Command";
CM_ SG_ 639 PEPS_LOCK_CMD "PEPS Lock and unlock Command";
CM_ SG_ 639 PEPS_FOB_NUM "FOB Identification (2 Fobs in advance)";
CM_ SG_ 639 PEPS_TrunkSWstatus "PEPS Trunk SW status";
CM_ SG_ 497 TPMS_FLTyreWarn "Front Left Tyre Warning
BCM目前没有高压报警，0x3:  High pressure预留";
CM_ SG_ 497 TPMS_FLTyre_Temperature "Front Left High Temperature";
CM_ SG_ 497 TPMS_FLTyre_Fast_Leak "Front Left Fast Leak";
CM_ SG_ 497 TPMS_FLTyre_Sensor_Failure "FL Sensor Failure";
CM_ SG_ 497 TPMS_FRTyreWarn "Front Right Tyre Warning
BCM目前没有高压报警，0x3:  High pressure预留";
CM_ SG_ 497 TPMS_FRTyre_Temperature "Front Right High Temperature";
CM_ SG_ 497 TPMS_FRTyre_Fast_Leak "Front Right Fast Leak";
CM_ SG_ 497 TPMS_FRTyre_Sensor_Failure "FR Sensor Failure";
CM_ SG_ 497 TPMS_RLTyreWarn "Rear Left Tyre Warning
BCM目前没有高压报警，0x3:  High pressure预留";
CM_ SG_ 497 TPMS_RLTyre_Temperature "Rear Left High Temperature";
CM_ SG_ 497 TPMS_RLTyre_Fast_Leak "Rear Left Fast Leak";
CM_ SG_ 497 TPMS_RLTyre_Sensor_Failure "RL Sensor Failure";
CM_ SG_ 497 TPMS_RRTyreWarn "Rear Right Tyre Warning
BCM目前没有高压报警，0x3:  High pressure预留";
CM_ SG_ 497 TPMS_RRTyre_Temperature "Rear Right High Temperature";
CM_ SG_ 497 TPMS_RRTyre_Fast_Leak "Rear Right Fast Leak";
CM_ SG_ 497 TPMS_RRTyre_Sensor_Failure "Rear Right Sensor Failure";
CM_ SG_ 497 TPMS_SystemSt "TPMS System Status";
CM_ BO_ 498 "TPMS information";
CM_ SG_ 498 TPMS_FLTyrePr "Front Left Tyre Pressure";
CM_ SG_ 498 TPMS_FRTyrePr "Front Right Tyre Pressure";
CM_ SG_ 498 TPMS_RLTyrePr "Rear Left Tyre Pressure";
CM_ SG_ 498 TPMS_RRTyrePr "Rear Right Tyre Pressure";
CM_ SG_ 498 TPMS_FLTyreTemp "Front Left TyreTemp";
CM_ SG_ 498 TPMS_FRTyreTemp "Front Right TyreTemp";
CM_ SG_ 498 TPMS_RLTyreTemp "Rear Left TyreTemp";
CM_ SG_ 498 TPMS_RRTyreTemp "Rear Right TyreTemp";
CM_ BO_ 880 "TPMS Status information";
CM_ SG_ 880 TPMS_FLTyrePrSts "The front left wheel tire pressure sensor learning status
左前轮胎压传感器学习状态";
CM_ SG_ 880 TPMS_FRTyrePrSts "The front right wheel tire pressure sensor learning status
右前轮胎压传感器学习状态";
CM_ SG_ 880 TPMS_RLTyrePrSts "The rear left wheel tire pressure sensor learning status
左后轮胎压传感器学习状态";
CM_ SG_ 880 TPMS_RRTyrePrSts "The rear right wheel tire pressure sensor learning status
右后轮胎压传感器学习状态";
CM_ SG_ 880 TPMS_FLTyreTempWarn "The front left wheel sensor battery voltage warning.
左前轮传感器电压低告警";
CM_ SG_ 880 TPMS_FRTyreTempWarn "The front right wheel sensor battery voltage warning.
右前轮传感器电压低告警";
CM_ SG_ 880 TPMS_RLTyreTempWarn "The rear left wheel sensor battery voltage warning.
左后轮传感器电压低告警";
CM_ SG_ 880 TPMS_RRTyreTempWarn "The rear right wheel sensor battery voltage warning.
右后轮传感器电压低告警";
CM_ BO_ 496 "Transmitted by BCM,including lamp status singals";
CM_ SG_ 496 BCM_TurnIndicatorLeft "Signal from BCM to indicate the ON/OFF status of Left Turn bubble";
CM_ SG_ 496 BCM_TurnIndicatorRight "Signal from BCM to indicate the ON/OFF status of Right Turn bubble";
CM_ SG_ 496 BCM_TurnLeverSts "BCM indicates turn lever's states";
CM_ SG_ 496 BCM_HighBeamLeverSts "High Beam Lever Status";
CM_ SG_ 496 BCM_HighBeamRelayFailSts "High beam relay failure status";
CM_ SG_ 496 BCM_LowBeamSts "Low Beam State";
CM_ SG_ 496 BCM_AutoLightSts "Auto-light State";
CM_ SG_ 496 BCM_HighBeamSts "Signal from BCM to indicate High beam status";
CM_ SG_ 496 BCM_PositionLightSts "Signal from BCM to indicate Position status";
CM_ SG_ 496 BCM_DayRunningLightSts "Signal from BCM to indicate day running light status";
CM_ SG_ 496 BCM_FollowMeHomACCMtive "Follow Me Home Active
BCM目前没有此置位，预留，此项GE12默认为60s，不需要设置";
CM_ SG_ 496 BCM_FrontFogLightSts "Signal from BCM to indicate front fog light status";
CM_ SG_ 496 BCM_RearFogLightSts "Signal from BCM to indicate rear fog light status";
CM_ SG_ 496 BCM_LightLeftOn "When you left ,this signal from BCM to indicate the  light not put down";
CM_ SG_ 496 BCM_LightLeftwarning "When all the situations have been meet，BCM will send the Light Not put down to TBOX:
1)IG OFF;
2)Position Light on;
3)Lock the door by RKE or Machenical KEY;
4)all situation has been meet,BCM will be timeing for 3 minutes, and no warning in 3 minutes.";
CM_ SG_ 496 BCM_HazardSts "hazard flashing status";
CM_ SG_ 496 BCM_LightChimeReq_AliveCounter "the AliveCounter of BCM_LightChimeReq message";
CM_ SG_ 496 BCM_LightChimeReq_CheckSum "the Checksum of the BCM_LightChimeReq message";
CM_ SG_ 645 BCM_Drv_Wdw_valid "driver window valid status";
CM_ SG_ 645 BCM_Drv_Val_Wdw_Opened "driver window Opened Value";
CM_ SG_ 645 BCM_Drv_Wdw_OD_Sts "driver window obstacle detection status";
CM_ SG_ 645 BCM_Drv_Wdw_Obs_InhibitSts "driver window Obstacle inhibit status";
CM_ SG_ 645 BCM_Drv_Wdw_Running_Sts "Running status of driver window    ";
CM_ SG_ 645 BCM_Drv_Wdw_PositionSts "Position status of driver window";
CM_ SG_ 645 BCM_Drv_Wdw_Error "driver window Error status";
CM_ SG_ 645 BCM_RLD_Wdw_valid "RL window valid status";
CM_ SG_ 645 BCM_RLD_Val_Wdw_Opened "RL window Opened Value";
CM_ SG_ 645 BCM_RLD_Wdw_OD_Sts "RL window Obstacle detection status";
CM_ SG_ 645 BCM_RLD_Wdw_Obs_InhibitSts "RL window Obstacle inhibit status";
CM_ SG_ 645 BCM_RLD_Wdw_Running_Sts "Running status of Rear Left window    ";
CM_ SG_ 645 BCM_RLD_Wdw_PositionSts "Position status of Rear Left window    ";
CM_ SG_ 645 BCM_RLD_Wdw_Error "RL window Error status";
CM_ SG_ 645 BCM_FrontLeftDoorAjarStatus "Signal from BCM to indicate the ajar/close status of driver door";
CM_ SG_ 645 BCM_RearLeftDoorAjarStatus "Signal from BCM to indicate the ajar/close status of Rear Left Door";
CM_ SG_ 645 BCM_DoorLockStatusDrv "Driver Door Lock Status";
CM_ SG_ 645 BCM_RearMirrorFoldSetResp "Rear view mirror automatic folding set Response";
CM_ SG_ 645 BCM_AntiPinchWarnSetResp "window anti-pinch warning set Response";
CM_ SG_ 646 BCM_Pas_Wdw_valid "passenger window valid status";
CM_ SG_ 646 BCM_Pas_Val_Wdw_Opened "passengerwindow Opened Value";
CM_ SG_ 646 BCM_Pas_Wdw_OD_Sts "passengerwindow Obstacle inhibit status";
CM_ SG_ 646 BCM_Pas_Wdw_Obs_InhibitSts "passengerwindow Obstacle inhibit status";
CM_ SG_ 646 BCM_Pas_Wdw_Running_Sts "Running status of passager window    ";
CM_ SG_ 646 BCM_Pas_Wdw_PositionSts "Position status of passager window    ";
CM_ SG_ 646 BCM_Pas_Wdw_Error "passenger window Error status";
CM_ SG_ 646 BCM_RRD_Wdw_valid "RR window valid status";
CM_ SG_ 646 BCM_RRD_Val_Wdw_Opened "RR window Opened Value";
CM_ SG_ 646 BCM_RRD_Wdw_OD_Sts "RR window Obstacle detection status";
CM_ SG_ 646 BCM_RRD_Wdw_Obs_InhibitSts "RR window Obstacle inhibit status";
CM_ SG_ 646 BCM_RRD_Wdw_Running_Sts "Running status of Rear Right window    ";
CM_ SG_ 646 BCM_RRD_Wdw_PositionSts "Position status of Rear Right window    ";
CM_ SG_ 646 BCM_RRD_Wdw_Error "RR window Error status";
CM_ SG_ 646 BCM_FrontRightDoorAjarStatus "Signal from BCM to indicate the ajar/close status of passenger door";
CM_ SG_ 646 BCM_RearRightDoorAjarStatus "Signal from BCM to indicate the ajar/close status of Rear Right Door";
CM_ BO_ 644 "Transmitted by BCM,including control switch and Rear window defroster Status singals";
CM_ SG_ 644 BCM_RearDefrosterSts "Signal from BCM to indicate if Rear window defroster relay is activated ";
CM_ SG_ 644 BCM_HandBreakSts "BCM send hand break sts";
CM_ SG_ 644 BCM_Central_Lock_CMD "BCM send central lock command";
CM_ SG_ 644 BCM_Central_unLock_CMD "BCM send central unlock command";
CM_ SG_ 644 BCM_WiperSts "Front wiper state ";
CM_ SG_ 644 BCM_HoodAjarStatus "Signal from BCM to indicate the ajar/close status of Hoodlid";
CM_ SG_ 644 BCM_TrunkAjarStatus "Signal from BCM to indicate the ajar/close status of Truncklid";
CM_ SG_ 644 BCM_IGNOFFUnlockDoorSelectResp "Select to unlock no door/ unlock driver door/ unlock all 4 doors at IGN OFF response";
CM_ SG_ 644 BCM_DoorLockUnlockCmd "Send Door Lock or Unlock command";
CM_ SG_ 644 BCM_AutoCloseWindowSetResp "Auto close/ open windlow set";
CM_ SG_ 644 BCM_ATWSHistory "Signal from BCM to indicate IPK to show ATWS history record";
CM_ SG_ 644 BCM_ATWS_St "BCM Anti thelf warning status";
CM_ SG_ 644 BCM_ATWarnTypeSetResp "Anti theft warn type set response";
CM_ SG_ 644 BCM_Warning_IMMO_Fail "immobilizer authentication failure";
CM_ BO_ 647 "Transmitted by BCM, including Front Window Status and Sunroff Status Signals";
CM_ SG_ 647 BCM_Odometerbackup "Backup odometer from EMS";
CM_ SG_ 647 L_Sunroof_Operation_State "Sunroof Operation state";
CM_ SG_ 647 L_sunroof_valid "Sunroof valid status";
CM_ SG_ 647 L_sunroof_Val_Opened "sunroof horizontal opened value";
CM_ SG_ 647 L_sunroof_ap_event "sunroof anti pinch triggered";
CM_ SG_ 647 L_sunroof_Error "sunroof Error status";
CM_ SG_ 647 L_Sunroof_Position "Actual Sunroof position";
CM_ BO_ 1025 "BCM Network management Message";
CM_ SG_ 1025 BCM_Address "ECU Address";
CM_ SG_ 1025 BCM_RMR "Repeat Message Request";
CM_ SG_ 1025 BCM_AWB "Active Wakeup Bit";
CM_ SG_ 1025 BCM_NMSts "The bit is used to indicate network management state. It's only used for test.";
CM_ SG_ 336 EPS_EpasFailed "转向故障位";
CM_ SG_ 704 EPS_StreeingWheelAngle "方向盘转向角";
CM_ BO_ 290 "Transmitted by ABS, including Front wheel speed signals";
CM_ SG_ 290 ABS_FLWheelSpeedKPH "Signal from ABS to indicate the front left wheel speed in kph";
CM_ SG_ 290 ABS_FLWheelSpeedInvalid "signal to identify if the wheel speed value valid";
CM_ SG_ 290 ABS_FRWheelSpeedKPH "Signal from ABS to indicate the front right wheel speed in kph";
CM_ SG_ 290 ABS_FRWheelSpeedInvalid "signal to identify if the wheel speed value valid";
CM_ SG_ 290 ABS_FWSpeedsKPH_AliveCounter "signal couting the times of this message";
CM_ SG_ 290 ABS_FWSpeedsKPH_CheckSum "CRC code to check the data integrity";
CM_ BO_ 291 "Transmitted by ABS, including Rear wheel speed signals";
CM_ SG_ 291 ABS_RLWheelSpeedKPH "Signal from ABS to indicate the rear left wheel speed in kph";
CM_ SG_ 291 ABS_RLWheelSpeedInvalid "signal to identify if the wheel speed value valid";
CM_ SG_ 291 ABS_RRWheelSpeedKPH "Signal from ABS to indicate the rear right wheel speed in kph";
CM_ SG_ 291 ABS_RRWheelSpeedInvalid "signal to identify if the wheel speed value valid";
CM_ SG_ 291 ABS_RWSpeedsKPH_AliveCounter "signal couting the times of this message";
CM_ SG_ 291 ABS_RWSpeedsKPH_CheckSum "CRC code to check the data integrity";
CM_ BO_ 292 "Transmitted by ABS, including 4 wheel speed pulse signals";
CM_ SG_ 292 ABS_FLWheelSpeedRC "Signal from ABS to indicate the front left wheel speed pulse";
CM_ SG_ 292 ABS_FRWheelSpeedRC "Signal from ABS to indicate the front right wheel speed pulse";
CM_ SG_ 292 ABS_RLWheelSpeedRC "Signal from ABS to indicate the rear left wheel speed pulse";
CM_ SG_ 292 ABS_RRWheelSpeedRC "Signal from ABS to indicate the rear right wheel speed pulse";
CM_ SG_ 292 ABS_FLWheelSpeedRCSts "Signal from ABS to indicate the front left ";
CM_ SG_ 292 ABS_FRWheelSpeedRCSts "Signal from ABS to indicate the front right wheel speed pulse";
CM_ SG_ 292 ABS_RLWheelSpeedRCSts "Signal from ABS to indicate the rear left wheel speed pulse";
CM_ SG_ 292 ABS_RRWheelSpeedRCSts "Signal from ABS to indicate the rear right wheel speed pulse";
CM_ SG_ 292 ABS_WheelSpeedsRC_AliveCounter "signal couting the times of this message";
CM_ SG_ 292 ABS_WheelSpeedsRC_CheckSum "CRC code to check the data integrity";
CM_ BO_ 293 "Transmitted by ABS, including ABS status ,Vehicle Speed and Brake switch status";
CM_ SG_ 293 ABSActive "Signal from ABS/ABS to indicate if ABS is activate or not";
CM_ SG_ 293 ABS_EBDFailed "Signal from ABS/ABS to indicate EBD failure for driver";
CM_ SG_ 293 ABSFailed "Signal from ABS/ABS to indicate Failure/Normal state of current running";
CM_ SG_ 293 ABS_VehicleSpeed "Vehicle Speed";
CM_ SG_ 293 ABS_VehicleSpeedInvalid "Signal from ABS to indicate if VehicleSpeed is valid";
CM_ SG_ 293 ABS_Status_AliveCounter "Message Rolling counter";
CM_ SG_ 293 ABS_HAZActive "Emergency Stop Active";
CM_ SG_ 293 ABS_Status_CheckSum "ABS_Status checksum ";
CM_ BO_ 896 "Transmitted by ACU , including ACU status， crash signals and warning signals";
CM_ SG_ 896 ACU_DrvSeatbeltBucklestatus "Signal from ACU for Driver seat belt warning indicator display on IPK
ACU信号提示主驾驶安全带未系";
CM_ SG_ 896 ACU_PassSeatbeltBucklestatus "Signal from ACU for Passenger seat belt warning indicator display on IPK
ACU信号提示副驾驶安全带未系";
CM_ SG_ 896 ACU_PassSeatOccupantSensorStat "Signal from ACU for Passenter seat belt warning indicator display on IPK
ACU信号提示副驾驶承重信号";
CM_ SG_ 896 ACU_AirbagWarningStatus "Signal from ACU for Airbag Controll Unit Warning LED status displaying on IPK";
CM_ SG_ 896 ACU_CrashOutputSts "Indicates the Crash Output Status";
CM_ SG_ 896 ACU_RollingCounter "Message counter for ACCMh transmitted ACU_FuelCutOffReq  . 0->15 overflows will come back to 0";
CM_ SG_ 896 ACU_Checksum "CRC code to check the data integrity";
CM_ BO_ 565 "VCU for Indication Message";
CM_ SG_ 565 VCU_IPK_NeedBrk "Need Brake Pressed ";
CM_ SG_ 565 VCU_GSMPosition "GSM Position";
CM_ SG_ 565 VCU_IPK_PumpFaultCode2 "PumpFaultCode";
CM_ SG_ 565 VCU_IPK_PumpAlarm "Pump Alarm";
CM_ SG_ 565 VCU_ChgConnectStsWarning "Charging connection status Warning";
CM_ SG_ 565 VCU_IPK_stChgElock "Status of Charge Elock";
CM_ SG_ 565 VCU_IPK_BatOverHeat "Battery Over Heat";
CM_ SG_ 565 VCU_IPK_12VBatVolt "Signal from VCU to indicate the VCU supplied voltage level";
CM_ BO_ 1059 "VCU Network Management Message";
CM_ SG_ 1059 VCU_Address "ECU Address";
CM_ SG_ 1059 VCU_RMR "Repeat Message Request";
CM_ SG_ 1059 VCU_ActiveWakeupBit "Active Wakeup Bit";
CM_ SG_ 1059 VCU_WakeUp_Reasons "Reasons for  awakening";
CM_ SG_ 1059 VCU_NMSts "The bit is used to indicate network management state. It's only used for test.";
CM_ SG_ 1059 VCU_StayAwake_Reasons "Reasons for staying awake";
CM_ BO_ 354 "Transmitted by GW";
CM_ SG_ 354 VCU_ePTModeActual "Indicates driver select ePT system Mode";
CM_ SG_ 354 VCU_Warning_IMMO_Fail "Indicates the IMMO Fail reason";
CM_ SG_ 354 VCU_ChargerFault "Indicates Charger Fault Lamp On";
CM_ SG_ 354 VCU_BrakeLampOn "VCU command BCM to activate the brak light";
CM_ SG_ 354 VCU_ePTReady "Indicates ePT system Ready State";
CM_ SG_ 354 VCU_ePTReleaseSig "PEPS receives ePT Locked signal from VCU";
CM_ SG_ 354 VCU_ePTRegencyLevInd "Indicates ePT Regency Level";
CM_ SG_ 354 VCU_Ctrl_AliveCounter "the AliveCounter of BCM_LightChimeReq message";
CM_ SG_ 354 VCU_DoubleFlashLampOn "VCU command BCM to activate the double flash light";
CM_ SG_ 354 VCU_LimpHomeSts "EMS_LimpHome to TCU should be replaced by VCU_LimpHome which considers both engine and BSG.";
CM_ SG_ 354 VCU_TurtleLampOn "VCU command IPK to activate the Turtle light";
CM_ SG_ 354 VCU_ePTFault "Indicates ePT system Fault State";
CM_ SG_ 354 VCU_Ctrl_CheckSum "the Checksum of the BCM_LightChimeReq message";
CM_ BO_ 357 "Transmitted by GW";
CM_ SG_ 357 VCU_ModeGearDisplaySts "Display the gear information";
CM_ SG_ 357 VCU_ModeControl_AliveCounter "signal couting the times of this message";
CM_ SG_ 357 VCU_ModeControl_CheckSum "CRC code to check the data integrity";
CM_ BO_ 421 "Transmitted by GW";
CM_ SG_ 421 VCU_CruiseControlSts "Cruise Control status (CC)";
CM_ SG_ 421 VCU_CruiseSwitchSts "Cruise Switch status";
CM_ SG_ 421 VCU_ControlSetSpeed "Cruise or ASLD control set speed";
CM_ SG_ 421 VCU_CSControl1_AliveCounter "signal couting the times of this message";
CM_ SG_ 421 VCU_CSControl1_CheckSum "CRC code to check the data integrity";
CM_ BO_ 1010 "Transmitted by GW, including Total Odometer";
CM_ SG_ 1010 VCU_Odometerbackup "Backup odometer from VCU";
CM_ BO_ 544 "Transmitted by GW";
CM_ SG_ 544 OBC_OnBdChrgrCCline "Status of the Onboard Charger connection to the grid";
CM_ SG_ 544 OBC_0x2B6_TimeoutFlag "Signal from GW to indicate the timeout of the source message dected by GW.
Indicating the following signals whether timeout:
1.OBC_OnBdChrgrCCline(源信号OBC_StsChgCC)
";
CM_ BO_ 168 "Transmitted by IPU, including actual ISG speed, torque";
CM_ SG_ 168 IPU_IsgSpdActSgn "speed with sign (+/-)";
CM_ SG_ 168 IPU_TrqSpd_AliveCounter "signal couting the times of this message";
CM_ SG_ 168 IPU_0x0C9_TimeoutFlag "Signal from GW to indicate the timeout of the source message dected by GW.
Indicating the following signals whether timeout:
1.IPU_IsgSpdActSgn（源信号IPU_MotorSpd)
";
CM_ SG_ 168 IPU_TrqSpd_Checksum "CRC code to check the data integrity";
CM_ BO_ 358 "Transmitted by GW";
CM_ SG_ 358 VCU_ModeSts "行驶模式信号";
CM_ SG_ 358 AC_AmbientTemperatureInvalid "Signal from AC indicate the ambient temperature invalid flag";
CM_ SG_ 358 VCU_AmbientTemperature "Signal from AC indicate the ambient temperature data";
CM_ SG_ 358 VCU_BatteryElectricDTE "The DTE odometer dsiplayed in IPK
仪表显示的纯电可续航里程";
CM_ SG_ 358 VCU_StsBrakePedalSwitch "Brake pedal Switch status";
CM_ SG_ 358 VCU_StatusAliveCounter "signal couting the times of this message";
CM_ SG_ 358 VCU_StatusCheckSum "CRC code to check the data integrity";
CM_ BO_ 157 "Transmitted by GW";
CM_ SG_ 157 EMS_EngineSpeedRPM "Signal from EMS/PowerTrian to indicate Engine RPM ";
CM_ SG_ 157 EMS_EngineSpeedRPMInvalid "Invalid flag for EMS_EngineSpeedRPM";
CM_ SG_ 157 EMS_EngStatus "Engine running status";
CM_ BO_ 592 "Transmitted by GW, indicates IPU, BMSH status";
CM_ SG_ 592 BMSH_BattCurr "Actual Battery current ，positive discharging,negative charging";
CM_ SG_ 592 BMSH_HVBusVolt "Actual HV Bus Voltage";
CM_ SG_ 592 BMSH_FastChgCC2ConntState "fast_chargeCC2_Connect_State";
CM_ SG_ 592 BMSH_BattFaultLampState "battery system Fault Lamp State";
CM_ SG_ 592 BMSH_ChargeLEDCtrl "charge status  indicate
";
CM_ SG_ 592 BMSH_0x0BA_TimeoutFlag "Signal from GW to indicate the timeout of the source message dected by GW.
Indicating the following signals whether timeout:
1. BMSH_BatCurrent
2. BMSH_HVBusVolt(源信号BMSH_BusVolt)";
CM_ SG_ 592 BMSH_0x0B9_TimeoutFlag "Signal from GW to indicate the timeout of the source message dected by GW.
Indicating the following signals whether timeout:
1. BMSH_ChargeLEDCtrl（源信号BMSH_StsMode）
2. BMSH_FastChgCC2ConntState(源信号BMSH_StsCC2）
3.BMSH_BattFaultLampState（源信号BMSH_VCU_DischgF";
CM_ SG_ 592 IPU_0x368_TimeoutFlag "Signal from GW to indicate the timeout of the source message dected by GW.
Indicating the following signals whether timeout:
1. IPU_MotOverTemp（源信号IPU_MotOverTempAlarm
、 IPU_IPUOverTempAlarm
、IPU_MotOverTempFault
、IPU_IPUOverTempFault）";
CM_ SG_ 592 IPU_MotOverTemp "Over temperature downrating of the Isg to indicated";
CM_ BO_ 256 "Transmitted by EMS, including Authentication  information";
CM_ BO_ 756 "Transmitted by BMSH, including SOC and power  related signals ";
CM_ SG_ 756 BMSH_BattSOCDisp "Display value of battery state of charge";
CM_ BO_ 379 "Transmitted by BMSH, including battery voltage 、current";
CM_ SG_ 379 BMSH_ACChgTimeRemain "Residue ChangeTime";
CM_ BO_ 570 "Transmitted by GW";
CM_ SG_ 570 VCU_PTCEnableWork "PTC enable";
CM_ SG_ 570 VCU_PTCAllowPwr "PTC Allow Power";
CM_ SG_ 570 VCU_PTCTargetTempReq "PTC Target Temperature Request";
CM_ SG_ 570 VCU_ACControlAliveCounter "signal couting the times of this message";
CM_ SG_ 570 VCU_ACControlCheckSum "CRC code to check the data integrity";
CM_ BO_ 359 "Electric Powertrain System Status";
CM_ SG_ 359 VCU_IPK_BatCutOff "Battery Cut Off";
CM_ SG_ 359 VCU_StsSysFault "Drive system fault level";
CM_ SG_ 359 VCU_AccPedalPosition "Accelerate pedal position";
CM_ SG_ 359 VCU_StsInsulation "Insulation status";
CM_ SG_ 359 VCU_StsBrkSwitch2 "Brake switch2 status";
CM_ SG_ 359 VCU_StsBrkSwitch1 "Brake switch1 status";
CM_ SG_ 359 VCU_StsBrakeFault "Brake fault status";
CM_ SG_ 359 VCU_StsAccPedalFault "Accelerate pedal fault status";
CM_ SG_ 359 VCU_StsAuxHVIL "Status of Auxiliary HVIL";
CM_ SG_ 359 VCU_StsMainHVIL "Status of Bat HVIL";
CM_ SG_ 359 VCU_IPK_ICSts "Intelligent Charge Status";
CM_ SG_ 359 VCU_StsChgHVIL "Status of Chg HVIL";
CM_ SG_ 359 VCU_StsEpt_AliveCounter "Signal counting the times of this message";
CM_ SG_ 359 VCU_StsEpt_CheckSum "Checksum of this message";
CM_ BO_ 571 "CCM Information Message";
CM_ SG_ 571 CCM_VCU_CCMPwrReq "CCM Request Power
(PTC & ACCM)";
CM_ SG_ 571 VCU_CCM_PwrAllow "CCM Allow Power";
CM_ SG_ 571 CCM_VCU_ActPTCPwr "PTC Actual Power";
CM_ SG_ 571 CCM_VCU_ActACCMPwr "ACCM Actual Power";
CM_ SG_ 571 VCU_CCM_EnableWork "CCM Enable";
CM_ SG_ 571 VCUCCM_Info_AliveCounter "Signal counting the times of this message";
CM_ SG_ 571 VCUCCM_Info_CheckSum "Checksum of this message";
CM_ BO_ 1031 "MMI Network management Message";
CM_ SG_ 1031 MMI_Address "ECU Address";
CM_ SG_ 1031 MMI_RMR "Repeat Message Request";
CM_ SG_ 1031 MMI_AWB "Active Wakeup Bit";
CM_ SG_ 1031 MMI_NMSts "The bit is used to indicate network management state. It's only used for test.";
CM_ SG_ 679 MMI_AVASDisabledSet "AVAS Disabled Set";
CM_ SG_ 673 MMI_Sunroof_TiltControl "Sunroof tilt control command";
CM_ SG_ 673 MMI_Drv_ControlCommand "driver window control command";
CM_ SG_ 673 MMI_Pas_ControlCommand "passenger window control command";
CM_ SG_ 673 MMI_RLD_ControlCommand "Rear Left window control command";
CM_ SG_ 673 MMI_RRD_ControlCommand "Rear Right window control command";
CM_ SG_ 673 MMI_Sunroof_StopCommand "BCM Stop commard to sunroof open or close";
CM_ SG_ 673 MMI_Sunroof_HorizontalControl "Sunroof horizontal control command";
CM_ SG_ 673 MMI_SunroofRollshade_Select "Sunroof or Rollshade control select";
BA_DEF_ BO_  "GenMsgSendType" ENUM  "Cycle","NoSendType","IfActive";
BA_DEF_ BO_  "GenMsgCycleTime" INT 0 0;
BA_DEF_ SG_  "GenSigSendType" ENUM  "Cycle","OnChange","OnWrite","IfActive","OnChangeWithRepetition","OnWriteWithRepetition","IfActiveWithRepetition";
BA_DEF_ SG_  "GenSigStartValue" INT 0 0;
BA_DEF_  "DBName" STRING ;
BA_DEF_ BU_  "NodeLayerModules" STRING ;
BA_DEF_ BU_  "ILUsed" ENUM  "No","Yes";
BA_DEF_ BU_  "NmNode" ENUM  "Not","Yes";
BA_DEF_  "NmBaseAddress" HEX 0 2047;
BA_DEF_  "NmMessageCount" INT 0 255;
BA_DEF_ BO_  "GenMsgILSupport" ENUM  "No","Yes";
BA_DEF_  "BusType" STRING ;
BA_DEF_ SG_  "SystemSignalLongSymbol" STRING ;
BA_DEF_DEF_  "GenMsgSendType" "Cycle";
BA_DEF_DEF_  "GenMsgCycleTime" 0;
BA_DEF_DEF_  "GenSigSendType" "Cycle";
BA_DEF_DEF_  "GenSigStartValue" 0;
BA_DEF_DEF_  "DBName" "";
BA_DEF_DEF_  "NodeLayerModules" "CANoeILNLVector.dll";
BA_DEF_DEF_  "ILUsed" "Yes";
BA_DEF_DEF_  "NmNode" "Not";
BA_DEF_DEF_  "NmBaseAddress" 1024;
BA_DEF_DEF_  "NmMessageCount" 128;
BA_DEF_DEF_  "GenMsgILSupport" "Yes";
BA_DEF_DEF_  "BusType" "CAN";
BA_DEF_DEF_  "SystemSignalLongSymbol" "";
BA_ "DBName" "BCAN";
BA_ "GenMsgCycleTime" BO_ 658 100;
BA_ "GenMsgSendType" BO_ 259 1;
BA_ "GenMsgCycleTime" BO_ 671 1000;
BA_ "GenMsgSendType" BO_ 1040 1;
BA_ "GenMsgCycleTime" BO_ 676 100;
BA_ "GenMsgCycleTime" BO_ 621 100;
BA_ "GenMsgCycleTime" BO_ 1009 1000;
BA_ "GenMsgCycleTime" BO_ 1015 1000;
BA_ "GenMsgSendType" BO_ 1026 1;
BA_ "GenMsgCycleTime" BO_ 626 100;
BA_ "GenMsgCycleTime" BO_ 482 20;
BA_ "GenMsgSendType" BO_ 257 1;
BA_ "GenMsgCycleTime" BO_ 624 100;
BA_ "GenMsgSendType" BO_ 258 1;
BA_ "GenMsgSendType" BO_ 639 1;
BA_ "GenMsgCycleTime" BO_ 497 50;
BA_ "GenMsgCycleTime" BO_ 498 50;
BA_ "GenMsgCycleTime" BO_ 880 500;
BA_ "GenMsgCycleTime" BO_ 496 50;
BA_ "GenMsgCycleTime" BO_ 645 100;
BA_ "GenMsgCycleTime" BO_ 646 100;
BA_ "GenMsgCycleTime" BO_ 644 100;
BA_ "GenMsgCycleTime" BO_ 647 100;
BA_ "GenMsgSendType" BO_ 1025 1;
BA_ "GenMsgCycleTime" BO_ 336 20;
BA_ "GenMsgCycleTime" BO_ 704 100;
BA_ "GenMsgCycleTime" BO_ 290 20;
BA_ "GenMsgCycleTime" BO_ 291 20;
BA_ "GenMsgCycleTime" BO_ 292 20;
BA_ "GenMsgCycleTime" BO_ 293 20;
BA_ "GenMsgCycleTime" BO_ 690 100;
BA_ "GenMsgCycleTime" BO_ 896 200;
BA_ "GenMsgCycleTime" BO_ 565 200;
BA_ "GenMsgSendType" BO_ 1059 1;
BA_ "GenMsgCycleTime" BO_ 354 20;
BA_ "GenMsgCycleTime" BO_ 357 20;
BA_ "GenMsgCycleTime" BO_ 421 20;
BA_ "GenMsgCycleTime" BO_ 1010 1000;
BA_ "GenMsgCycleTime" BO_ 544 100;
BA_ "GenMsgCycleTime" BO_ 168 10;
BA_ "GenMsgCycleTime" BO_ 358 20;
BA_ "GenMsgCycleTime" BO_ 157 10;
BA_ "GenMsgCycleTime" BO_ 592 100;
BA_ "GenMsgSendType" BO_ 256 1;
BA_ "GenMsgCycleTime" BO_ 756 100;
BA_ "GenMsgCycleTime" BO_ 379 200;
BA_ "GenMsgCycleTime" BO_ 570 100;
BA_ "GenMsgCycleTime" BO_ 359 20;
BA_ "GenMsgCycleTime" BO_ 571 500;
BA_ "GenMsgCycleTime" BO_ 554 100;
BA_ "GenMsgCycleTime" BO_ 550 100;
BA_ "GenMsgSendType" BO_ 1031 1;
BA_ "GenMsgCycleTime" BO_ 679 100;
BA_ "GenMsgCycleTime" BO_ 673 100;
BA_ "GenSigStartValue" SG_ 3221225472 ACU_PassengerAirbagStatus 1;
BA_ "GenSigStartValue" SG_ 555 PTC_IGBTTemp 40;
BA_ "GenSigStartValue" SG_ 555 PTC_CIntTempInlet 40;
BA_ "GenSigSendType" SG_ 259 TBOX_ResponseCode 2;
BA_ "GenSigStartValue" SG_ 671 TBOX_Day 1;
BA_ "GenSigStartValue" SG_ 671 TBOX_Month 1;
BA_ "GenSigSendType" SG_ 1040 TBOX_Information_Address 2;
BA_ "GenSigSendType" SG_ 1040 TBOX_RMR 2;
BA_ "GenSigSendType" SG_ 1040 TBOX_AWB 2;
BA_ "GenSigSendType" SG_ 1040 TBOX_Wakeup_reasons 2;
BA_ "GenSigSendType" SG_ 1040 TBOX_NMSts 2;
BA_ "GenSigSendType" SG_ 1040 TBOX_Stayawake_reasons 2;
BA_ "GenSigStartValue" SG_ 1009 IPK_ServiceMaintainInterval 65535;
BA_ "GenSigSendType" SG_ 1026 IPK_Address 2;
BA_ "GenSigSendType" SG_ 1026 IPK_RMR 2;
BA_ "GenSigSendType" SG_ 1026 IPK_AWB 2;
BA_ "GenSigSendType" SG_ 1026 IPK_Wakeup_reasons 2;
BA_ "GenSigSendType" SG_ 1026 IPK_NMSts 2;
BA_ "GenSigSendType" SG_ 1026 IPK_Stayawake_reasons 2;
BA_ "SystemSignalLongSymbol" SG_ 626 PEPS_Indication_press_brake_clut "PEPS_Indication_press_brake_clutch";
BA_ "GenSigSendType" SG_ 257 PEPS_IMMOCode 2;
BA_ "GenSigSendType" SG_ 258 PEPS_TELchallengeCode 2;
BA_ "GenSigSendType" SG_ 639 PEPS_KeyreminderUnlock 2;
BA_ "GenSigSendType" SG_ 639 PEPS_RKECommand 2;
BA_ "GenSigSendType" SG_ 639 PEPS_LOCK_CMD 2;
BA_ "GenSigSendType" SG_ 639 PEPS_FOB_NUM 2;
BA_ "GenSigSendType" SG_ 639 PEPS_TrunkSWstatus 2;
BA_ "GenSigStartValue" SG_ 498 TPMS_FLTyreTemp 205;
BA_ "GenSigStartValue" SG_ 498 TPMS_FRTyreTemp 205;
BA_ "GenSigStartValue" SG_ 498 TPMS_RLTyreTemp 205;
BA_ "GenSigStartValue" SG_ 645 BCM_DoorLockStatusDrv 2;
BA_ "GenSigSendType" SG_ 1025 BCM_Address 2;
BA_ "GenSigSendType" SG_ 1025 BCM_RMR 2;
BA_ "GenSigSendType" SG_ 1025 BCM_AWB 2;
BA_ "GenSigSendType" SG_ 1025 BCM_Wakeup_reasons 2;
BA_ "GenSigSendType" SG_ 1025 BCM_NMSts 2;
BA_ "GenSigSendType" SG_ 1025 BCM_Stayawake_reasons 2;
BA_ "GenSigStartValue" SG_ 290 ABS_FLWheelSpeedInvalid 1;
BA_ "GenSigStartValue" SG_ 290 ABS_FRWheelSpeedInvalid 1;
BA_ "GenSigStartValue" SG_ 291 ABS_RLWheelSpeedInvalid 1;
BA_ "GenSigStartValue" SG_ 291 ABS_RRWheelSpeedInvalid 1;
BA_ "GenSigStartValue" SG_ 293 ABS_EBDFailed 1;
BA_ "GenSigStartValue" SG_ 293 ABSFailed 1;
BA_ "GenSigStartValue" SG_ 565 VCU_GSMPosition 3;
BA_ "GenSigSendType" SG_ 1059 VCU_Address 2;
BA_ "GenSigSendType" SG_ 1059 VCU_RMR 2;
BA_ "GenSigSendType" SG_ 1059 VCU_ActiveWakeupBit 2;
BA_ "GenSigSendType" SG_ 1059 VCU_WakeUp_Reasons 2;
BA_ "GenSigSendType" SG_ 1059 VCU_NMSts 2;
BA_ "GenSigSendType" SG_ 1059 VCU_StayAwake_Reasons 2;
BA_ "GenSigStartValue" SG_ 357 VCU_ModeGearDisplaySts 31;
BA_ "GenSigStartValue" SG_ 358 VCU_AmbientTemperature 20;
BA_ "GenSigSendType" SG_ 256 IPU_PEPSAuth 2;
BA_ "GenSigStartValue" SG_ 756 BMSH_BattSOCDisp 50;
BA_ "GenSigSendType" SG_ 1031 MMI_Address 2;
BA_ "GenSigSendType" SG_ 1031 MMI_RMR 2;
BA_ "GenSigSendType" SG_ 1031 MMI_AWB 2;
BA_ "GenSigSendType" SG_ 1031 MMI_Wakeup_reasons 2;
BA_ "GenSigSendType" SG_ 1031 MMI_NMSts 2;
BA_ "GenSigSendType" SG_ 1031 MMI_Stayawake_reasons 2;
BA_ "GenSigStartValue" SG_ 673 MMI_Drv_ControlCommand 127;
BA_ "GenSigStartValue" SG_ 673 MMI_Pas_ControlCommand 127;
BA_ "GenSigStartValue" SG_ 673 MMI_RLD_ControlCommand 127;
BA_ "GenSigStartValue" SG_ 673 MMI_RRD_ControlCommand 127;
BA_ "GenSigStartValue" SG_ 673 MMI_Sunroof_HorizontalControl 127;
VAL_ 3221225472 ACU_PassengerAirbagStatus 0 "PAB disable　副驾驶安全气囊无作用" 1 "PAB enable　副驾驶安全气囊使能" ;
VAL_ 3221225472 ACCM_ACCMError 0 "无错误" 1 "运行过流；保护关机" 2 "运行过压；保护关机" 4 "运行欠压；保护关机" 8 "待机过压；" 16 "待机欠压；" 32 "数据处理故障；" 64 "过流降频； (压缩机电流大于10.5A时进行降频运行)" 128 "过功率降频；" 256 "过温保护：" 512 "相电流保护：" 1024 "运行失步：" 2048 "启动失败：" 4096 "通讯失败：" 8192 "控制器自检故障：" ;
VAL_ 555 PTC_MmryFlt 1 "ture" 0 "false" ;
VAL_ 555 PTC_IGBTTemSnsrFlt 1 "Ture" 0 "False" ;
VAL_ 555 PTC_ClntInltTemSnsrFlt 1 "ture" 0 "false" ;
VAL_ 555 PTC_ClntOtltTemSnsrFlt 1 "Ture" 0 "False" ;
VAL_ 555 PTC_CommError 1 "ture" 0 "false" ;
VAL_ 555 PTC_CoreOrIGBTOpenErr 1 "ture" 0 "false" ;
VAL_ 555 PTC_IGBTShrtErr 1 "ture" 0 "false" ;
VAL_ 555 PTC_CoreShrtErr 1 "ture" 0 "false" ;
VAL_ 555 PTC_HVOverCrntProtn 1 "ture" 0 "false" ;
VAL_ 555 PTC_VbatVtgProtn 1 "ture" 0 "false" ;
VAL_ 555 PTC_HVDisconnectProtn 1 "ture" 0 "false" ;
VAL_ 555 PTC_IGBTOverTemProtn 1 "ture" 0 "false" ;
VAL_ 555 PTC_ClntInltOverTemProtn 1 "ture" 0 "false" ;
VAL_ 555 PTC_ClntOtltOverTemProtn 1 "Ture" 0 "False" ;
VAL_ 555 PTC_PCBOverTempProtn 1 "ture" 0 "false" ;
VAL_ 658 TBOX_All_Door_Lock 0 "No command" 1 "All door lock" 2 "Blink lamp  闪灯" 3 "All door unlock" 4 "Whistle    鸣笛" 5 "Global closing-window up" 6 "Closing window" 7 "Closing sunroof" 8 "Global opening-window down" 9 "Vehicle search" 10 "Trunk unlock" 11 "Window ventilate" 12 "Opening sunroof" ;
VAL_ 1040 TBOX_RMR 0 "Repeat Message State not requested" 1 "Repeat Message State requested" ;
VAL_ 1040 TBOX_AWB 0 "Node has not woken up the network (passive wakeup)" 1 "Node has woken up the network (active Wakeup)" ;
VAL_ 1040 TBOX_Wakeup_reasons 0 "Default" 1 "Reserved" 2 "NM PDU Received" 3 "Reserved" 4 "Reserved" 5 "KL15 On" 6 "Telematics service" ;
VAL_ 1040 TBOX_NMSts 0 "Repeat Message State" 1 "Normal Operation State" ;
VAL_ 676 MMI_RightSwStatus 0 "No press" 1 "Short Press" 2 "Long Press" 3 "LongPressNotRelease" ;
VAL_ 676 MMI_LeftSwStatus 0 "No press" 1 "Short Press" 2 "Long Press" 3 "LongPressNotRelease" ;
VAL_ 676 MMI_UpSwStatus 0 "No press" 1 "Short Press" 2 "Long Press" 3 "LongPressNotRelease" ;
VAL_ 676 MMI_DownSwStatus 0 "No press" 1 "Short Press" 2 "Long Press" 3 "LongPressNotRelease" ;
VAL_ 676 MMI_ConfirmSwStatus 0 "No press" 1 "Short Press" 2 "Long Press" 3 "LongPressNotRelease" ;
VAL_ 676 MMI_WorkMode 0 "MMI mode" 1 "IPK mode" 2 "HUD mode_Reserved" 3 "Reserved" ;
VAL_ 676 MMI_ePTRegencyLevRequest 0 "No Request" 1 "Request Regency Leve1低" 2 "Request Regency Leve2中" 3 "Request Regency Leve3高" ;
VAL_ 676 MMI_Backlightadjust 0 "No Action" 1 "Level 1" 2 "Level 2" 3 "Level 3" 4 "Level 4" 5 "Level 5" 6 "Level 6" 7 "Level 7" 8 "Level 8" 9 "Level 9" 10 "Level 10" 31 "Invalid" ;
VAL_ 621 IPK_AirbagUnitLEDSts 0 "ACU  LED Off" 1 "ACU  LED On" 2 "ACU  LED Blinking(Reserved)" 3 "ACU LED Error or Status Unknown" ;
VAL_ 621 IPK_Fail 0 "NO error" 1 "error" ;
VAL_ 621 IPK_AverageVehicleSpeed 255 "Invalid value" ;
VAL_ 621 IPK_MaintanceWarningSts 0 "No warning" 1 "Warning" ;
VAL_ 621 IPK_Backlightadjust 0 "No Action" 1 "Level 1" 2 "Level 2" 3 "Level 3" 4 "Level 4" 5 "Level 5" 6 "Level 6" 7 "Level 7" 8 "Level 8" 9 "Level 9" 10 "Level 10" 31 "Invalid" ;
VAL_ 621 IPK_vDisplay 8191 "Invalid" ;
VAL_ 1009 IPK_IPKTotalOdometer 16777214 "Abnormal" 16777215 "Invalid" ;
VAL_ 1009 IPK_OdometerbackupEnable 0 "Disable" ;
VAL_ 1009 IPK_ServiceMaintainInterval 65535 "Invalid" ;
VAL_ 1015 IPK_AveragePowerConsumption 8191 "Invalid" ;
VAL_ 1015 IPK_InstantPowerConsumption 8191 "Invalid" ;
VAL_ 1026 IPK_RMR 0 "Repeat Message State not requested" 1 "Repeat Message State requested" ;
VAL_ 1026 IPK_AWB 0 "Node has not woken up the network (passive wakeup)" 1 "Node has woken up the network (active Wakeup)" ;
VAL_ 1026 IPK_Wakeup_reasons 0 "Default" 1 "KL15" 2 "NM PDU Received" ;
VAL_ 1026 IPK_NMSts 0 "Repeat Message State" 1 "Normal Operation State" ;
VAL_ 626 PEPS_Warning_No_key_found 0 "No warning" 1 "Warning" ;
VAL_ 626 PEPS_Indication_press_brake_clut 0 "No warning" 1 "Warning" ;
VAL_ 626 PEPS_Indication_shift_to_PN 0 "No warning" 1 "Warning" ;
VAL_ 626 PEPS_Indication_shift_to_Park 0 "No warning" 1 "Warning" ;
VAL_ 626 PEPS_IGN1FailureWarning 0 "No warning" 1 "Warning" ;
VAL_ 626 PEPS_Warning_UID_LOW_BATT 0 "No warning" 1 "Warning" ;
VAL_ 626 PEPS_Indication_UID_Closer 0 "No warning" 1 "Warning" ;
VAL_ 626 PEPS_Warning_keyInReminder_2 0 "No warning" 1 "Warning" ;
VAL_ 626 PEPS_SSB_Failure_warning 0 "No warning" 1 "Warning" ;
VAL_ 626 PEPS_TerminalNotOFF_Warning 0 "No warning" 1 "Warning" ;
VAL_ 626 PEPS_AnyDoorOpen_Warning 0 "No warning" 1 "Warning" ;
VAL_ 626 PEPS_KeyInReminderCfgResult 0 "Disable" 1 "Enable" ;
VAL_ 626 PEPS_TerminalNotOFFWarnCfgResult 0 "Disable" 1 "Enable" ;
VAL_ 626 PEPS_AnyDoorOpenWarnCfgResult 0 "Disable" 1 "Enable" ;
VAL_ 482 PEPS_PowerModeValidity 0 "Not available" 1 "Invalid" 2 "Valid" 3 "Reserved" ;
VAL_ 482 PEPS_PowerMode 0 "OFF" 1 "ACC" 2 "ON" 3 "Reserved" 4 "START" ;
VAL_ 482 PEPS_RemoteControlSt 0 "Not Remote control mode" 1 "Remote control mode" ;
VAL_ 482 PEPS_IGN1RelayValidity 0 "Invalid" 1 "Valid" ;
VAL_ 482 PEPS_ACCRelaySts 0 "Inactive" 1 "Active" ;
VAL_ 482 PEPS_IGN1RelaySts 0 "Inactive" 1 "Active" ;
VAL_ 482 PEPS_Learning_Status 0 "Busy" 1 "Virgin" 2 "Learnt" 3 "Neutralized" ;
VAL_ 624 PEPS_StatusResponse2TBOX 0 "Default" 1 "Received(in progress)" 2 "Success" 3 "Failed" ;
VAL_ 624 PEPS_TELAuthenStatus 0 "Default" 1 "Fail" 2 "Pass" 3 "Reserved" ;
VAL_ 624 PEPS_FailReason2TBOX 0 "No fail reason" 1 "Wrong command" 2 "Termial NOT OFF" 3 "Voltage out of range" 4 "TeleOption not set" 5 "Speed Invalid" 6 "Vehicle is moving" 7 "Any door opened(4door )" 8 "Key in the car" 9 "PEPS not learnt" 10 "Communication error" 11 "Any door not locked" 12 "Any window not closed" 13 "Brake is pressed" 14 "ATWS status not armed" 15 "IGN1 output failure" 16 "Starter output failure" 17 "P position failure" 18 "SSB pressed" 19 "Telematic authentication failure" 20 "EMS auth failed" 21 "EMS no response" 22 "Max engine running timer expired" 23 "Transition to normal power mode" 24 "Remote engine off request" 25 "Reset caused quiting" 26 "Engine forbid function not support" 27 "Multiple command received" 28 "Command validity via CAN is invalid" 29 "hood is open" 30 "Trunk open" 31 "Engine not run" 32 "EPB not parking state" 33 "ATWS Ststus is alarm" 34 "No Valid fob found" 35 "GearPosition is not PN" 36 "Any door not unlocked" 37 "Exceed Maximum engine start time" 38 "OBC connection is on" 39 "Exceed Maximum engine start retry time during one driving cycle" 40 "Remote Engine Start is already in working" 41 "Trunk open failure" 42 "Window open failed" ;
VAL_ 639 PEPS_KeyreminderUnlock 0 "No command" 1 "Unlock" ;
VAL_ 639 PEPS_RKECommand 0 "No command" 1 "All door lock" 2 "Tailgate button short press" 3 "All door unlock" 4 "Trunk unlock/Tailgate button long press" 5 "Global closing —window up" 6 "Global opening —window down" 7 "Global action stop—window move stop(reserved)" 8 "Silent/Sound shift BCM" 9 "Vehicle search" 10 "Window ventilate" 11 "Sunroof close" 12 "Sunroof open" ;
VAL_ 639 PEPS_LOCK_CMD 0 "No command" 1 "All door lock" 2 "Reserved" 3 "All door unlock" 4 "Trunk unlock" 5 "Global closing--window up" 6 "Reserved" 7 "Reserved" ;
VAL_ 639 PEPS_FOB_NUM 0 "initial" 1 "key index 1" 2 "key index 2" 3 "key index 3" 4 "key index 4" ;
VAL_ 639 PEPS_TrunkSWstatus 0 "No press" 1 "Press" ;
VAL_ 497 TPMS_FLTyreWarn 0 "Normal Pressure" 1 "Pre-warning low Pressure (Reserved)" 2 "Low pressure" 3 "High pressure" ;
VAL_ 497 TPMS_FLTyre_Temperature 0 "Normal Temperature" 1 "High Temperature" ;
VAL_ 497 TPMS_FLTyre_Fast_Leak 0 "Normal Pressure" 1 "Pressure fast leak" ;
VAL_ 497 TPMS_FLTyre_Sensor_Failure 0 "No Sensor Failure" 1 "Sensor Failure" ;
VAL_ 497 TPMS_FRTyreWarn 0 "Normal Pressure" 1 "Pre-warning low Pressure (Reserved)" 2 "Low pressure" 3 "High pressure" ;
VAL_ 497 TPMS_FRTyre_Temperature 0 "Normal Temperature" 1 "High Temperature" ;
VAL_ 497 TPMS_FRTyre_Fast_Leak 0 "Normal Pressure" 1 "Pressure fast leak" ;
VAL_ 497 TPMS_FRTyre_Sensor_Failure 0 "No Sensor Failure" 1 "Sensor Failure" ;
VAL_ 497 TPMS_RLTyreWarn 0 "Normal Pressure" 1 "Pre-warning low Pressure (Reserved)" 2 "Low pressure" 3 "High pressure" ;
VAL_ 497 TPMS_RLTyre_Temperature 0 "Normal Temperature" 1 "High Temperature" ;
VAL_ 497 TPMS_RLTyre_Fast_Leak 0 "Normal Pressure" 1 "Pressure fast leak" ;
VAL_ 497 TPMS_RLTyre_Sensor_Failure 0 "No Sensor Failure" 1 "Sensor Failure" ;
VAL_ 497 TPMS_RRTyreWarn 0 "Normal Pressure" 1 "Pre-warning low Pressure (Reserved)" 2 "Low pressure" 3 "High pressure" ;
VAL_ 497 TPMS_RRTyre_Temperature 0 "Normal Temperature" 1 "High Temperature" ;
VAL_ 497 TPMS_RRTyre_Fast_Leak 0 "Normal Pressure" 1 "Pressure fast leak" ;
VAL_ 497 TPMS_RRTyre_Sensor_Failure 0 "No Sensor Failure" 1 "Sensor Failure" ;
VAL_ 497 TPMS_SystemSt 0 "System OK" 1 "System Not OK" 2 "pressure unnormal" 3 "Reserved" ;
VAL_ 498 TPMS_FLTyrePr 255 "Invalid" ;
VAL_ 498 TPMS_FRTyrePr 255 "Invalid" ;
VAL_ 498 TPMS_RLTyrePr 255 "Invalid" ;
VAL_ 498 TPMS_RRTyrePr 255 "Invalid" ;
VAL_ 498 TPMS_FLTyreTemp 255 "Invalid" ;
VAL_ 498 TPMS_FRTyreTemp 255 "Invalid" ;
VAL_ 498 TPMS_RLTyreTemp 255 "Invalid" ;
VAL_ 498 TPMS_RRTyreTemp 255 "Invalid" ;
VAL_ 880 TPMS_FLTyrePrSts 0 "Virgin" 1 "Learnt" ;
VAL_ 880 TPMS_FRTyrePrSts 0 "Virgin" 1 "Learnt" ;
VAL_ 880 TPMS_RLTyrePrSts 0 "Virgin" 1 "Learnt" ;
VAL_ 880 TPMS_RRTyrePrSts 0 "Virgin" 1 "Learnt" ;
VAL_ 880 TPMS_FLTyreTempWarn 0 "Normal" 1 "Low" ;
VAL_ 880 TPMS_FRTyreTempWarn 0 "Normal" 1 "Low" ;
VAL_ 880 TPMS_RLTyreTempWarn 0 "Normal" 1 "Low" ;
VAL_ 880 TPMS_RRTyreTempWarn 0 "Normal" 1 "Low" ;
VAL_ 496 BCM_TurnIndicatorLeft 0 "OFF" 1 "ON" ;
VAL_ 496 BCM_TurnIndicatorRight 0 "OFF" 1 "ON" ;
VAL_ 496 BCM_TurnLeverSts 0 "Inactive" 1 "Turn left" 2 "Turn right" 3 "Error status" ;
VAL_ 496 BCM_HighBeamLeverSts 0 "Switch OFF" 1 "Switch ON" ;
VAL_ 496 BCM_HighBeamRelayFailSts 0 "Normal" 1 "Failure" ;
VAL_ 496 BCM_LowBeamSts 0 "OFF" 1 "ON" ;
VAL_ 496 BCM_AutoLightSts 0 "OFF" 1 "ON" ;
VAL_ 496 BCM_HighBeamSts 0 "OFF" 1 "ON" ;
VAL_ 496 BCM_PositionLightSts 0 "OFF" 1 "ON" ;
VAL_ 496 BCM_DayRunningLightSts 0 "Inactive" 1 "Active" ;
VAL_ 496 BCM_FollowMeHomACCMtive 0 "inactive" 1 "Active" ;
VAL_ 496 BCM_FrontFogLightSts 0 "OFF" 1 "ON" ;
VAL_ 496 BCM_RearFogLightSts 0 "OFF" 1 "ON" ;
VAL_ 496 BCM_LightLeftOn 0 "Inactive" 1 "Active" ;
VAL_ 496 BCM_LightLeftwarning 0 "Inactive" 1 "Active" ;
VAL_ 496 BCM_HazardSts 0 "Inactive" 1 "Active" ;
VAL_ 645 BCM_Drv_Wdw_valid 0 "Invalid" 1 "Valid" ;
VAL_ 645 BCM_Drv_Val_Wdw_Opened 127 "Invalid" ;
VAL_ 645 BCM_Drv_Wdw_OD_Sts 0 "Non anti-pinch status" 1 "In Anti-pinch status" ;
VAL_ 645 BCM_Drv_Wdw_Obs_InhibitSts 0 "Not Obs Inhibit status" 1 "Obs Inhibit status" ;
VAL_ 645 BCM_Drv_Wdw_Running_Sts 0 "Window stop" 1 "Manual Up" 2 "Manual Down" 3 "Auto Up" 4 "Auto Down" ;
VAL_ 645 BCM_Drv_Wdw_PositionSts 0 "Middle position" 1 "Complete Open" 2 "Complete Close" 3 "Invalid" ;
VAL_ 645 BCM_Drv_Wdw_Error 0 "No Error" 1 "Error" ;
VAL_ 645 BCM_RLD_Wdw_valid 0 "Invalid" 1 "Valid" ;
VAL_ 645 BCM_RLD_Val_Wdw_Opened 127 "Invalid" ;
VAL_ 645 BCM_RLD_Wdw_OD_Sts 0 "Non anti-pinch status" 1 "In Anti-pinch status" ;
VAL_ 645 BCM_RLD_Wdw_Obs_InhibitSts 0 "Not Obs Inhibit status" 1 "Obs Inhibit status" ;
VAL_ 645 BCM_RLD_Wdw_Running_Sts 0 "Window stop" 1 "Manual Up" 2 "Manual Down" 3 "Auto Up" 4 "Auto Down" ;
VAL_ 645 BCM_RLD_Wdw_PositionSts 0 "Middle position" 1 "Complete Open" 2 "Complete Close" 3 "Invalid" ;
VAL_ 645 BCM_RLD_Wdw_Error 0 "No Error" 1 "Error" ;
VAL_ 645 BCM_FrontLeftDoorAjarStatus 0 "DoorClosed" 1 "DoorAjar" ;
VAL_ 645 BCM_RearLeftDoorAjarStatus 0 "DoorClosed" 1 "DoorAjar" ;
VAL_ 645 BCM_DoorLockStatusDrv 0 "Unlocked" 1 "Locked" 2 "Reserved" 3 "Error (Reserved)" ;
VAL_ 645 BCM_RearMirrorFoldSetResp 0 "Disable" 1 "Enable" ;
VAL_ 645 BCM_AntiPinchWarnSetResp 0 "Disable" 1 "Enable" ;
VAL_ 646 BCM_Pas_Wdw_valid 0 "Invalid" 1 "Valid" ;
VAL_ 646 BCM_Pas_Val_Wdw_Opened 127 "Invalid" ;
VAL_ 646 BCM_Pas_Wdw_OD_Sts 0 "Non anti-pinch status" 1 "In Anti-pinch status" ;
VAL_ 646 BCM_Pas_Wdw_Obs_InhibitSts 0 "Not Obs Inhibit status" 1 "Obs Inhibit status" ;
VAL_ 646 BCM_Pas_Wdw_Running_Sts 0 "Window stop" 1 "Manual Up" 2 "Manual Down" 3 "Auto Up" 4 "Auto Down" ;
VAL_ 646 BCM_Pas_Wdw_PositionSts 0 "Middle position" 1 "Complete Open" 2 "Complete Close" 3 "Invalid" ;
VAL_ 646 BCM_Pas_Wdw_Error 0 "No Error" 1 "Error" ;
VAL_ 646 BCM_RRD_Wdw_valid 0 "Invalid" 1 "Valid" ;
VAL_ 646 BCM_RRD_Val_Wdw_Opened 127 "Invalid" ;
VAL_ 646 BCM_RRD_Wdw_OD_Sts 0 "Non anti-pinch status" 1 "In Anti-pinch status" ;
VAL_ 646 BCM_RRD_Wdw_Obs_InhibitSts 0 "Not Obs Inhibit status" 1 "Obs Inhibit status" ;
VAL_ 646 BCM_RRD_Wdw_Running_Sts 0 "Window stop" 1 "Manual Up" 2 "Manual Down" 3 "Auto Up" 4 "Auto Down" ;
VAL_ 646 BCM_RRD_Wdw_PositionSts 0 "Middle position" 1 "Complete Open" 2 "Complete Close" 3 "Invalid" ;
VAL_ 646 BCM_RRD_Wdw_Error 0 "No Error" 1 "Error" ;
VAL_ 646 BCM_FrontRightDoorAjarStatus 0 "DoorClosed" 1 "DoorAjar" ;
VAL_ 646 BCM_RearRightDoorAjarStatus 0 "DoorClosed" 1 "DoorAjar" ;
VAL_ 644 BCM_RearDefrosterSts 0 "Defroster Inactive" 1 "Defroster active" 2 "Reserved" 3 "Invalid" ;
VAL_ 644 BCM_HandBreakSts 0 "release" 1 "not release" ;
VAL_ 644 BCM_Central_Lock_CMD 0 "inactive" 1 "active" ;
VAL_ 644 BCM_Central_unLock_CMD 0 "inactive" 1 "active" ;
VAL_ 644 BCM_WiperSts 0 "OFF" 1 "Low speed" 2 "High speed" 3 "Undefined" 4 "Undefined" 5 "Undefined" 6 "Undefined" 7 "Invalid" ;
VAL_ 644 BCM_HoodAjarStatus 0 "HoodClosed" 1 "HoodAjar" 2 "Reserved" 3 "Invalid(Reserved)" ;
VAL_ 644 BCM_TrunkAjarStatus 0 "TrunkClosed" 1 "TrunkAjar" ;
VAL_ 644 BCM_IGNOFFUnlockDoorSelectResp 0 "Diasble （No request to unlock any door）" 1 "Enable（ Request driver door unlock）" 2 "reserved（ Request all doors unlock）" 3 "Reserved" ;
VAL_ 644 BCM_DoorLockUnlockCmd 0 "no command" 1 "All Dorr Lock" 2 "Driver Door Unlock" 3 "All Door Unlock" 4 "Reserved" 5 "Reserved" 6 "Reserved" 7 "Invalid" ;
VAL_ 644 BCM_AutoCloseWindowSetResp 0 "Disabled" 1 "Enable（Auto close/open by RKE key long press）" 2 "Auto close window by vehicle lock" 3 "Reserved" ;
VAL_ 644 BCM_ATWSHistory 0 "No History" 1 "Hood Intrusion" 2 "Trunk Intrusion" 3 "Front Left Door Intrusion" 4 "Front Right Door Intrusion" 5 "Rear Left Door Intrusion" 6 "Rear Right Door Intrusion" 7 "Reserved" ;
VAL_ 644 BCM_ATWS_St 0 "Armed" 1 "Prearmed" 2 "Disarmed" 3 "Remind" 4 "Alarm" 5 "Partially Armed" 6 "Not used" 7 "Not used" ;
VAL_ 644 BCM_ATWarnTypeSetResp 0 "Disable( No Request)仅灯光" 1 "Enable(Lighting and Horn)" 2 "Lighting(reserved)" 3 "Horn(reserved)" ;
VAL_ 644 BCM_Warning_IMMO_Fail 0 "No warning" 1 "Warning" ;
VAL_ 647 BCM_Odometerbackup 16383 "Invalid" ;
VAL_ 647 BCM_DoorLockPro 0 "Inactive" 1 "Active" ;
VAL_ 647 BCM_AnyDoorAjar 0 "Inactive" 1 "Active" ;
VAL_ 647 L_Sunroof_Operation_State 0 "Idle / Not pressed" 1 "Manual slide open" 2 "Manual slide close" 3 "Manual tilt open" 4 "Manual tilt close" 5 "Auto slide open" 6 "Auto slide close" 7 "Auto tilt open" 8 "Auto tilt close" 9 "Moving uninitialized" 10 "Reversing（防夹后反弹）" ;
VAL_ 647 L_sunroof_valid 0 "Invalid" 1 "Valid" ;
VAL_ 647 L_sunroof_Val_Opened 127 "Invalid" ;
VAL_ 647 L_sunroof_ap_event 0 "Anti pinch did not trigger" 1 "Anti pinch did trigger" ;
VAL_ 647 L_sunroof_Error 0 "No Error" 1 "Error" ;
VAL_ 647 L_Sunroof_Position 0 "Position unknwon/Invalid" 1 "Completely closed" 2 "Completely opened" 3 "Between tilt and open" 4 "Completely tilted" 5 "Between tilt and close" 6 "Slide open comfort position" 7 "Reserved" ;
VAL_ 1025 BCM_RMR 0 "Repeat Message State not requested" 1 "Repeat Message State requested" ;
VAL_ 1025 BCM_AWB 0 "Node has not woken up the network (passive wakeup)" 1 "Node has woken up the network (active Wakeup)" ;
VAL_ 1025 BCM_Wakeup_reasons 0 "Default" 1 "IGN status changes from IGN OFF/ACC to other status" 2 "Reserved" 3 "Reserved" 4 "NM PDU Received" 5 "Hazard switch pressed" 6 "Driver door ajar status change" 7 "Passenger door ajar status change" 8 "RL door ajar status change" 9 "RR door ajar status change" 10 "Hood door ajar status change" 11 "Trunk door ajar status change" 12 "Position light sw activated" 13 "High beam sw activated;" 14 "Driver door lock status change" 15 "Other three door lock status change" 16 "Mechnical Key Lock switch activated" 17 "ATWS status change" ;
VAL_ 1025 BCM_NMSts 0 "Repeat Message State" 1 "Normal Operation State" ;
VAL_ 336 EPS_EpasFailed 0 "NotFailed" 1 "Failed" ;
VAL_ 290 ABS_FLWheelSpeedKPH 8191 "Invalid" ;
VAL_ 290 ABS_FLWheelSpeedInvalid 0 "Valid" 1 "Invalid" ;
VAL_ 290 ABS_FRWheelSpeedKPH 8191 "Invalid" ;
VAL_ 290 ABS_FRWheelSpeedInvalid 0 "Valid" 1 "Invalid" ;
VAL_ 291 ABS_RLWheelSpeedKPH 8191 "Invalid" ;
VAL_ 291 ABS_RLWheelSpeedInvalid 0 "Valid" 1 "Invalid" ;
VAL_ 291 ABS_RRWheelSpeedKPH 8191 "Invalid" ;
VAL_ 291 ABS_RRWheelSpeedInvalid 0 "Valid" 1 "Invalid" ;
VAL_ 292 ABS_FLWheelSpeedRCSts 0 "Valid" 1 "Invalid" ;
VAL_ 292 ABS_FRWheelSpeedRCSts 0 "Valid" 1 "Invalid" ;
VAL_ 292 ABS_RLWheelSpeedRCSts 0 "Valid" 1 "Invalid" ;
VAL_ 292 ABS_RRWheelSpeedRCSts 0 "Valid" 1 "Invalid" ;
VAL_ 293 ABSActive 0 "Inactive" 1 "Active" ;
VAL_ 293 ABS_EBDFailed 0 "EBD Normal" 1 "EBD Failed" ;
VAL_ 293 ABSFailed 0 "ABS Normal" 1 "ABS Failed" ;
VAL_ 293 ABS_VehicleSpeed 8190 "Abnormal" 8191 "Invalid value" ;
VAL_ 293 ABS_VehicleSpeedInvalid 0 "Valid" 1 "Invalid" ;
VAL_ 293 ABS_HAZActive 0 "Emergency brake light off" 1 "Emergency brake light on" ;
VAL_ 690 AVAS_AVASDisabledSts 1 "Disable" 0 "Enable" ;
VAL_ 896 ACU_DrvSeatbeltBucklestatus 0 "safety belt tied(Switch off )安全带系上" 1 "safety belt not tied(Switch on)安全带未系 报警" ;
VAL_ 896 ACU_PassSeatbeltBucklestatus 0 "safety belt tied(Switch off )安全带系上" 1 "safety belt not tied(Switch on)安全带未系 报警" ;
VAL_ 896 ACU_PassSeatOccupantSensorStat 0 "Empty　　副驾驶座空" 1 "Occupied　副驾驶座承重" ;
VAL_ 896 ACU_AirbagWarningStatus 0 "OFF" 1 "ON" 2 "Flash_Reserved" 3 "Reserved" ;
VAL_ 565 VCU_IPK_PumpFaultCode1 0 "normal" 1 "真空泵总工作时间≥1500h报警" ;
VAL_ 565 VCU_IPK_PumpFaultCode6 1 "真空泄露报警" 0 "normal" ;
VAL_ 565 VCU_IPK_PumpFaultCode5 1 "真空度传感器故障" 0 "normal" ;
VAL_ 565 VCU_IPK_PumpFaultCode4 1 "自检不通过报警" 0 "normal" ;
VAL_ 565 VCU_IPK_PumpFaultCode3 1 "助力器真空度过低报警" 0 "normal" ;
VAL_ 565 VCU_IPK_MotFault 1 "Fault(故障)" 0 "Default(默认值)" ;
VAL_ 565 VCU_IPK_NeedBrk 0 "Default(默认)" 1 "Need Brake(需要踩刹车)" ;
VAL_ 565 VCU_GSMPosition 0 "Reserved(预留)" 1 "P Range(P档)(预留)" 2 "R Range(R档)" 3 "N Range(N档)" 4 "D Range(D档)" 7 "Fault(档位器故障)" ;
VAL_ 565 VCU_IPK_PumpFaultCode2 1 "真空泵循环次数≥1200000次报警" 0 "normal" ;
VAL_ 565 VCU_IPK_PumpAlarm 0 "Normal(正常)" 1 "Abnormity(异常)" ;
VAL_ 565 VCU_ChgConnectStsWarning 0 "Normal(正常)" 1 "Warning(提醒)" ;
VAL_ 565 VCU_IPK_stChgElock 0 "Unlock(未锁)" 1 "Lock(锁止)" 2 "Lock Fault(锁故障)" 3 "Invalid(无效)" ;
VAL_ 565 VCU_IPK_BatOverHeat 0 "Default(默认值)" 1 "OverHeat(过热)" ;
VAL_ 565 VCU_IPK_12VBatVolt 255 "Invalid(无效)" ;
VAL_ 1059 VCU_RMR 0 "Repeat Message State not requested" 1 "Repeat Message State requested" ;
VAL_ 1059 VCU_ActiveWakeupBit 0 "Node has not woken up the network" 1 "Node has woken up the network" ;
VAL_ 1059 VCU_NMSts 0 "Repeat Message State" 1 "Normal Operation State" ;
VAL_ 354 VCU_ePTModeActual 1 "Pure Electric Drive" 2 "Idle Charging" 3 "Parallel Drive" 4 "Smart Charging" 5 "Pure Engine Drive" 6 "Drive Charging" 7 "Regen Drive" ;
VAL_ 354 VCU_Warning_IMMO_Fail 0 "No warning" 1 "IPU_Fail" 2 "EMS_Fail" 3 "Both Fail" ;
VAL_ 354 VCU_ChargerFault 0 "False" 1 "True" ;
VAL_ 354 VCU_BrakeLampOn 0 "Inactive" 1 "Active" ;
VAL_ 354 VCU_ePTReady 0 "PTReady Not Active" 1 "PTReady Active" ;
VAL_ 354 VCU_ePTReleaseSig 0 "Undefined" 1 "ePT Released" 2 "ePT Locked" 3 "Reserved" ;
VAL_ 354 VCU_ePTRegencyLevInd 0 "Default" 1 "Regency Leve1" 2 "Regency Leve2" 3 "Regency Leve3" 4 "Regency Leve4" 5 "Reserved" 6 "Reserved" 7 "Reserved" ;
VAL_ 354 VCU_DoubleFlashLampOn 0 "Inactive" 1 "Active" ;
VAL_ 354 VCU_LimpHomeSts 0 "not in Limphome Mode" 1 "in Limphome Mode" ;
VAL_ 354 VCU_TurtleLampOn 0 "Lamp Off" 1 "Lamp On" ;
VAL_ 354 VCU_ePTFault 0 "False" 1 "True" ;
VAL_ 357 VCU_ModeGearDisplaySts 0 "NO Display" 1 "Display P（reserved）" 2 "Display R" 3 "Display N" 4 "Display D" 31 "Invalid" ;
VAL_ 421 VCU_CruiseControlSts 0 "CC off/standby" 1 "CC active" 2 "CC override (Reserved)" 3 "Accelerate" 4 "Decelerate" 5 "Resume last setspeed" 6 "tap + (increase setspeed)" 7 "tap – (decrease setspeed)" ;
VAL_ 421 VCU_CruiseSwitchSts 0 "Off" 1 "On" ;
VAL_ 421 VCU_ControlSetSpeed 255 "Invalid" ;
VAL_ 1010 VCU_Odometerbackup 16383 "Invalid" ;
VAL_ 544 OBC_OnBdChrgrCCline 0 "Not connected" 1 "Connected" 2 "Half-connected" 3 "CC signal failure" ;
VAL_ 544 OBC_0x2B6_TimeoutFlag 0 "Normal" 1 "Timeout" ;
VAL_ 168 IPU_IsgSpdActSgn 65534 "Abnormal" 65535 "Invalid" ;
VAL_ 168 IPU_0x0C9_TimeoutFlag 0 "Normal" 1 "Timeout" ;
VAL_ 358 VCU_ModeSts 0 "ECO" 1 "SPORT" ;
VAL_ 358 AC_AmbientTemperatureInvalid 0 "Ambient Temperature valid" 1 "Ambient Temperature invalid" ;
VAL_ 358 VCU_BatteryElectricDTE 1023 "Invalid" ;
VAL_ 358 VCU_StsBrakePedalSwitch 0 "Reserved(预留)" 1 "Not pressed(松开)" 2 "Pressed(踩下)" 3 "Invalid(无效)" ;
VAL_ 157 VCU_ModeGearDisplaySts_BCM 4 "D" 3 "P" 2 "R" 1 "reserved" 0 "Display" ;
VAL_ 157 EMS_EngineSpeedRPM 65534 "Abnormal" 65535 "Invalid" ;
VAL_ 157 EMS_EngineSpeedRPMInvalid 0 "Valid" 1 "Invalid" ;
VAL_ 157 EMS_EngStatus 0 "Engine Stop" 1 "Cranking" 2 "Stopping ( only for PHEV )" 3 "Running" 4 "Reserved" 5 "Reserved" 6 "Abnormal" 7 "Invalid" ;
VAL_ 592 BMSH_BattCurr 16382 "Abnornal" 16383 "Invalid" ;
VAL_ 592 BMSH_FastChgCC2ConntState 0 "disconnect" 1 "connect" 2 "连接异常（有插枪却无连接信号或者有连接信号却无快充唤醒）" ;
VAL_ 592 BMSH_BattFaultLampState 0 "Lamp off" 1 "Lamp on" 2 "Reserved" 3 "Reserved" ;
VAL_ 592 BMSH_ChargeLEDCtrl 0 "Default" 1 "Charging" 2 "Charge completed" 3 "Charge fault" 4 "Heating/cooling" 5 "Fail silent" ;
VAL_ 592 BMSH_0x0BA_TimeoutFlag 0 "Normal" 1 "Timeout" ;
VAL_ 592 BMSH_0x0B9_TimeoutFlag 0 "Normal" 1 "Timeout" ;
VAL_ 592 IPU_0x368_TimeoutFlag 0 "Normal" 1 "Timeout" ;
VAL_ 592 IPU_MotOverTemp 0 "False" 1 "True" ;
VAL_ 756 BMSH_BattSOCDisp 1022 "Abnormal" 1023 "Invalid" ;
VAL_ 570 VCU_ACCMEnable 0 "Not enable" 1 "Enable" ;
VAL_ 570 VCU_PTCEnableWork 0 "Not enable" 1 "Enable" ;
VAL_ 359 VCU_IPK_BatCutOff 0 "Default(默认值)" 1 "CutOff(断开)" ;
VAL_ 359 VCU_StsSysFault 0 "Init(初始化)(预留)" 1 "Normal(正常)" 3 "Warning(报警)" 5 "Derating(降功率)" 7 "Limphome(跛行回家)" 9 "ZeroTorque(零扭矩)" 11 "Powerdown(延迟下电)" 13 "EmPowerdown(紧急下电)" 15 "Invalid(无效)" ;
VAL_ 359 VCU_StsInsulation 0 "Normal(正常)" 1 "Fault Level I(1级故障)" 2 "Fault Level II(2级故障)" 3 "Reserved(预留)" ;
VAL_ 359 VCU_StsBrkSwitch2 0 "Not pressed(松开)" 1 "Pressed(踩下)" ;
VAL_ 359 VCU_StsBrkSwitch1 0 "Not pressed(松开)" 1 "Pressed(踩下)" ;
VAL_ 359 VCU_StsBrakeFault 0 "Normal(正常)" 1 "Fault(故障)" ;
VAL_ 359 VCU_StsAccPedalFault 0 "Valid(有效)" 1 "Invalid(无效)" ;
VAL_ 359 VCU_StsAuxHVIL 0 "Normal(正常)" 1 "Error(异常)" ;
VAL_ 359 VCU_StsMainHVIL 0 "Normal(正常)" 1 "Error(异常)" ;
VAL_ 359 VCU_IPK_ICSts 0 "NoFill(无补电)" 1 "Filling(补电中)" ;
VAL_ 359 VCU_StsChgHVIL 0 "Normal(正常)" 1 "Error(异常)" ;
VAL_ 571 CCM_VCU_CCMPwrReq 255 "Invalid(无效)" ;
VAL_ 571 VCU_CCM_PwrAllow 255 "Invalid(无效)" ;
VAL_ 571 CCM_VCU_ActPTCPwr 255 "Invalid(无效)" ;
VAL_ 571 CCM_VCU_ActACCMPwr 255 "Invalid(无效)" ;
VAL_ 571 VCU_CCM_EnableWork 0 "Not enable(不使能)" 1 "enable(使能)" ;
VAL_ 554 PTC_WorkingSts 0 "OFF" 1 "wait fault" 2 "sleep fault" 3 "operation" ;
VAL_ 550 ACCM_InnerCommunError 1 "Error" 0 "normal" ;
VAL_ 550 ACCM_SelfTestFail 1 "Error" 0 "normal" ;
VAL_ 550 ACCM_CommunFail 1 "Error" 0 "normal" ;
VAL_ 550 ACCM_StartFail 1 "Error" 0 "normal" ;
VAL_ 550 ACCM_Stepout 1 "Error" 0 "normal" ;
VAL_ 550 ACCM_CurProt 1 "Error" 0 "normal" ;
VAL_ 550 ACCM_OverTemp 1 "Error" 0 "normal" ;
VAL_ 550 ACCM_PowerLimit 1 "Error" 0 "normal" ;
VAL_ 550 ACCM_DataProError 1 "Error" 0 "normal" ;
VAL_ 550 ACCM_StandbyLowVolt 1 "Error" 0 "normal" ;
VAL_ 550 ACCM_StandbyOverVolt 1 "Error" 0 "normal" ;
VAL_ 550 ACCM_WokLowVolt 1 "Error" 0 "normal" ;
VAL_ 550 ACCM_OverVolt 1 "Error" 0 "normal" ;
VAL_ 550 ACCM_OverCur 1 "Error" 0 "normal" ;
VAL_ 550 ACCM_CompressorPower 255 "低压高压都有,但是压缩机不工作" 254 "只有低压没有高压,压缩机不工作" ;
VAL_ 550 ACCM_CompressorSpeed 255 "低压高压都有,但是压缩机不工作" 254 "只有低压没有高压,压缩机不工作" ;
VAL_ 550 ACCM_ACCMSts 0 "OFF" 1 "ON" 2 "reserved" 3 "Error" ;
VAL_ 1031 MMI_RMR 0 "Repeat Message State not requested" 1 "Repeat Message State requested" ;
VAL_ 1031 MMI_AWB 0 "Node has not woken up the network (passive wakeup)" 1 "Node has woken up the network (active Wakeup)" ;
VAL_ 1031 MMI_Wakeup_reasons 0 "Default" 1 "Reserved" 2 "NM PDU Received" 3 "Reserved" 4 "Reserved" 5 "ACC High" ;
VAL_ 1031 MMI_NMSts 0 "Repeat Message State" 1 "Normal Operation State" ;
VAL_ 679 MMI_Maintanceclear_inform 0 "inactive" 1 "active" ;
VAL_ 679 MMI_AVASDisabledSet 0 "No Request" 1 "Disable Request" 2 "Enable Request" 3 "Reserved" ;
VAL_ 673 MMI_AntiPinchWarnSet 3 "Reserved" 2 "Enable Request" 1 "Disable Request" 0 "No Request" ;
VAL_ 673 MMI_AutoCloseWindowSet 3 "Reserved" 2 "Enable Request" 1 "Disable Request" 0 "No Request" ;
VAL_ 673 MMI_K15Off_AutounlockSet 3 "Reserved" 2 "Enable Request" 1 "Disable Request" 0 "No Request" ;
VAL_ 673 MMI_RKELockFeedbackSet 3 "Reserved" 2 "Enable Request

" 1 "Disable Request" 0 "No Request" ;
VAL_ 673 MMI_Sunroof_TiltControl 0 "No Request" 1 "Tilt Open Request" 2 "Tilt Close Request" 3 "Reserved" ;
VAL_ 673 MMI_Drv_ControlCommand 127 "No Request" ;
VAL_ 673 MMI_Pas_ControlCommand 127 "No Request" ;
VAL_ 673 MMI_RLD_ControlCommand 127 "No Request" ;
VAL_ 673 MMI_RRD_ControlCommand 127 "No Request" ;
VAL_ 673 MMI_Sunroof_StopCommand 0 "Default" 1 "Stop Command" ;
VAL_ 673 MMI_Sunroof_HorizontalControl 127 "No Request" ;
VAL_ 673 MMI_SunroofRollshade_Select 0 "Sunroof" 1 "Rollshade" ;
